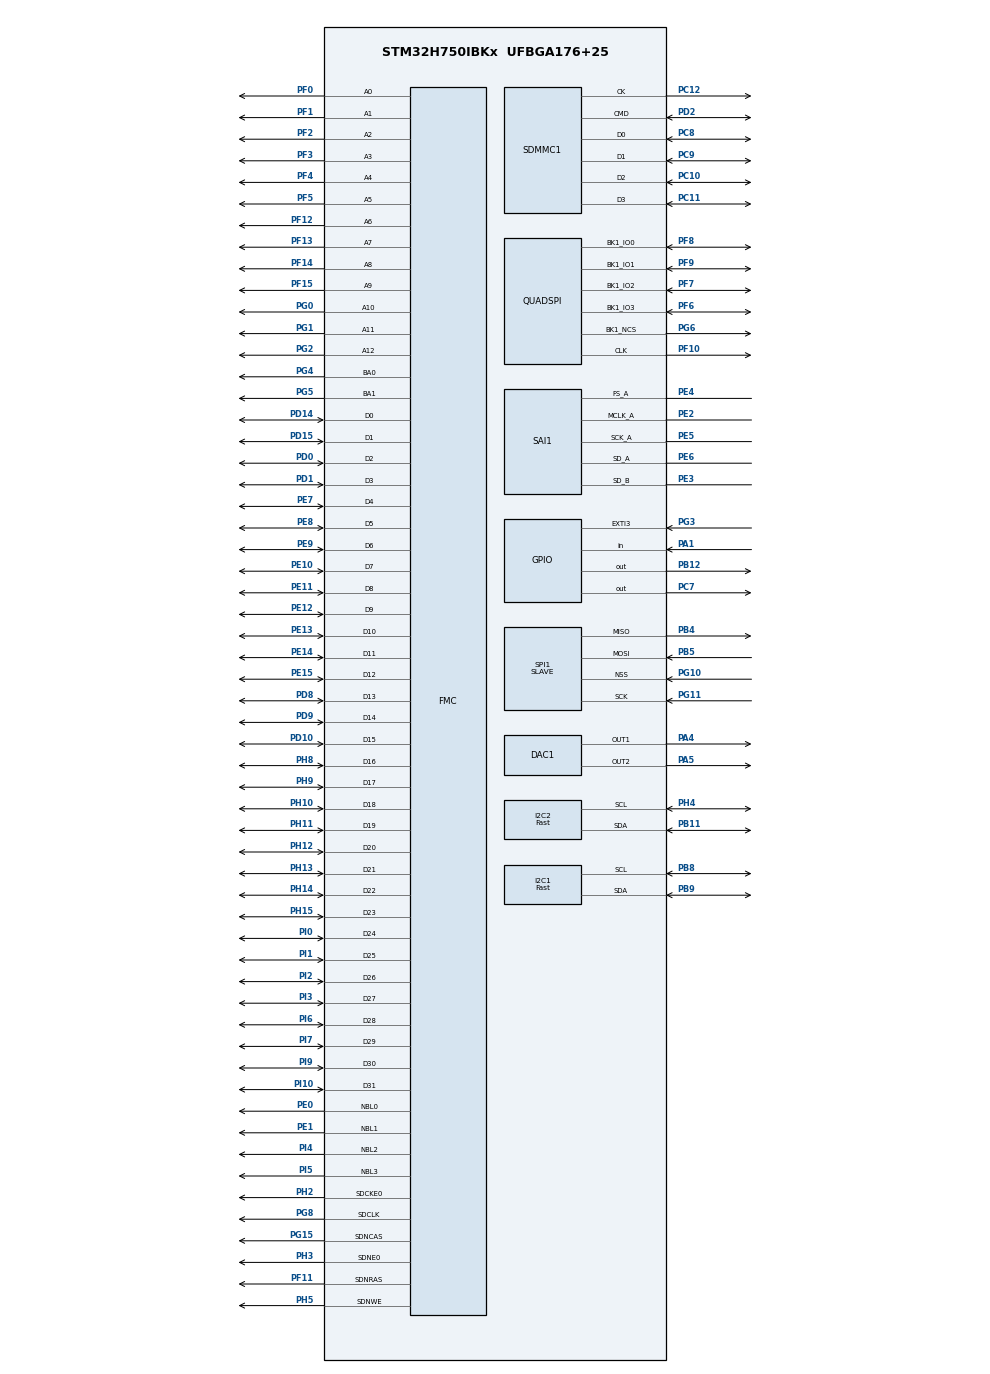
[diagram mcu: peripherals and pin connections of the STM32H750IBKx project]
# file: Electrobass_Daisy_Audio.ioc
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CORTEX_M7.CPU_DCache=Enabled
CORTEX_M7.CPU_ICache=Disabled
CORTEX_M7.default_mode_Activation=0
DAC1.DAC_Channel-DAC_OUT1=DAC_CHANNEL_1
DAC1.DAC_Channel-DAC_OUT2=DAC_CHANNEL_2
DAC1.DAC_Trigger-DAC_OUT1=DAC_TRIGGER_SOFTWARE
DAC1.DAC_Trigger-DAC_OUT2=DAC_TRIGGER_SOFTWARE
Dma.Request0=SAI1_A
Dma.Request1=SAI1_B
Dma.Request2=SPI1_RX
Dma.Request3=SPI1_TX
Dma.SAI1_A.0.Direction=DMA_PERIPH_TO_MEMORY
Dma.SAI1_A.0.EventEnable=ENABLE
Dma.SAI1_A.0.FIFOMode=DMA_FIFOMODE_DISABLE
Dma.SAI1_A.0.Instance=DMA1_Stream1
Dma.SAI1_A.0.MemDataAlignment=DMA_MDATAALIGN_WORD
Dma.SAI1_A.0.MemInc=DMA_MINC_ENABLE
Dma.SAI1_A.0.Mode=DMA_CIRCULAR
Dma.SAI1_A.0.PeriphDataAlignment=DMA_PDATAALIGN_WORD
Dma.SAI1_A.0.PeriphInc=DMA_PINC_DISABLE
Dma.SAI1_A.0.Polarity=HAL_DMAMUX_REQ_GEN_RISING
Dma.SAI1_A.0.Priority=DMA_PRIORITY_HIGH
Dma.SAI1_A.0.RequestNumber=1
Dma.SAI1_A.0.SignalID=NONE
Dma.SAI1_A.0.SyncEnable=ENABLE
Dma.SAI1_A.0.SyncPolarity=HAL_DMAMUX_SYNC_RISING
Dma.SAI1_A.0.SyncRequestNumber=1
Dma.SAI1_A.0.SyncSignalID=NONE
Dma.SAI1_B.1.Direction=DMA_MEMORY_TO_PERIPH
Dma.SAI1_B.1.EventEnable=DISABLE
Dma.SAI1_B.1.FIFOMode=DMA_FIFOMODE_DISABLE
Dma.SAI1_B.1.Instance=DMA1_Stream2
Dma.SAI1_B.1.MemDataAlignment=DMA_MDATAALIGN_WORD
Dma.SAI1_B.1.MemInc=DMA_MINC_ENABLE
Dma.SAI1_B.1.Mode=DMA_CIRCULAR
Dma.SAI1_B.1.PeriphDataAlignment=DMA_PDATAALIGN_WORD
Dma.SAI1_B.1.PeriphInc=DMA_PINC_DISABLE
Dma.SAI1_B.1.Polarity=HAL_DMAMUX_REQ_GEN_RISING
Dma.SAI1_B.1.Priority=DMA_PRIORITY_HIGH
Dma.SAI1_B.1.RequestNumber=1
Dma.SAI1_B.1.SignalID=NONE
Dma.SAI1_B.1.SyncEnable=DISABLE
Dma.SAI1_B.1.SyncPolarity=HAL_DMAMUX_SYNC_NO_EVENT
Dma.SAI1_B.1.SyncRequestNumber=1
Dma.SAI1_B.1.SyncSignalID=NONE
Dma.SPI1_RX.2.Direction=DMA_PERIPH_TO_MEMORY
Dma.SPI1_RX.2.EventEnable=DISABLE
Dma.SPI1_RX.2.FIFOMode=DMA_FIFOMODE_ENABLE
Dma.SPI1_RX.2.FIFOThreshold=DMA_FIFO_THRESHOLD_1QUARTERFULL
Dma.SPI1_RX.2.Instance=DMA1_Stream6
Dma.SPI1_RX.2.MemBurst=DMA_MBURST_SINGLE
Dma.SPI1_RX.2.MemDataAlignment=DMA_MDATAALIGN_BYTE
Dma.SPI1_RX.2.MemInc=DMA_MINC_ENABLE
Dma.SPI1_RX.2.Mode=DMA_CIRCULAR
Dma.SPI1_RX.2.PeriphBurst=DMA_PBURST_SINGLE
Dma.SPI1_RX.2.PeriphDataAlignment=DMA_PDATAALIGN_BYTE
Dma.SPI1_RX.2.PeriphInc=DMA_PINC_DISABLE
Dma.SPI1_RX.2.Polarity=HAL_DMAMUX_REQ_GEN_RISING
Dma.SPI1_RX.2.Priority=DMA_PRIORITY_VERY_HIGH
Dma.SPI1_RX.2.RequestNumber=1
Dma.SPI1_RX.2.SignalID=NONE
Dma.SPI1_RX.2.SyncEnable=DISABLE
Dma.SPI1_RX.2.SyncPolarity=HAL_DMAMUX_SYNC_NO_EVENT
Dma.SPI1_RX.2.SyncRequestNumber=1
Dma.SPI1_RX.2.SyncSignalID=NONE
Dma.SPI1_TX.3.Direction=DMA_MEMORY_TO_PERIPH
Dma.SPI1_TX.3.EventEnable=DISABLE
Dma.SPI1_TX.3.FIFOMode=DMA_FIFOMODE_ENABLE
Dma.SPI1_TX.3.FIFOThreshold=DMA_FIFO_THRESHOLD_1QUARTERFULL
Dma.SPI1_TX.3.Instance=DMA1_Stream7
Dma.SPI1_TX.3.MemBurst=DMA_MBURST_SINGLE
Dma.SPI1_TX.3.MemDataAlignment=DMA_MDATAALIGN_BYTE
Dma.SPI1_TX.3.MemInc=DMA_MINC_ENABLE
Dma.SPI1_TX.3.Mode=DMA_CIRCULAR
Dma.SPI1_TX.3.PeriphBurst=DMA_PBURST_SINGLE
Dma.SPI1_TX.3.PeriphDataAlignment=DMA_PDATAALIGN_BYTE
Dma.SPI1_TX.3.PeriphInc=DMA_PINC_DISABLE
Dma.SPI1_TX.3.Polarity=HAL_DMAMUX_REQ_GEN_RISING
Dma.SPI1_TX.3.Priority=DMA_PRIORITY_VERY_HIGH
Dma.SPI1_TX.3.RequestNumber=1
Dma.SPI1_TX.3.SignalID=NONE
Dma.SPI1_TX.3.SyncEnable=DISABLE
Dma.SPI1_TX.3.SyncPolarity=HAL_DMAMUX_SYNC_NO_EVENT
Dma.SPI1_TX.3.SyncRequestNumber=1
Dma.SPI1_TX.3.SyncSignalID=NONE
FATFS.BSP.number=1
FATFS.USE_DMA_CODE_SD=0
FATFS._FS_NORTC=0
FATFS._USE_FASTSEEK=0
FATFS._USE_FIND=1
FATFS._USE_LFN=1
FATFS0.BSP.STBoard=false
FATFS0.BSP.api=Unknown
FATFS0.BSP.instance=PA1
FATFS0.BSP.ip=GPIO
FATFS0.BSP.mode=Input
FATFS0.BSP.name=Detect_SDIO
FATFS0.BSP.solution=PA1
FMC.CASLatency1=FMC_SDRAM_CAS_LATENCY_3
FMC.ColumnBitsNumber1=FMC_SDRAM_COLUMN_BITS_NUM_9
FMC.ExitSelfRefreshDelay1=7
FMC.LoadToActiveDelay1=2
FMC.RCDDelay1=10
FMC.ReadBurst1=FMC_SDRAM_RBURST_ENABLE
FMC.ReadBurst2=FMC_SDRAM_RBURST_ENABLE
FMC.RowCycleDelay1=8
FMC.RowCycleDelay2=8
FMC.SDClockPeriod1=FMC_SDRAM_CLOCK_PERIOD_2
FMC.SDClockPeriod2=FMC_SDRAM_CLOCK_PERIOD_2
FMC.SelfRefreshTime1=4
FMC.WriteRecoveryTime1=3
I2C1.I2C_Rise_Time=300
I2C1.I2C_Speed_Mode=I2C_Fast
I2C1.Timing=0x30B00F2D
I2C2.I2C_Speed_Mode=I2C_Fast
I2C2.Timing=0x00B03FDB
Mcu.Family=STM32H7
Mcu.Name=STM32H750IBKx
Mcu.Package=UFBGA176+25
NVIC.DMA1_Stream1_IRQn=true\:3\:0\:true\:false\:true\:false\:true\:true
NVIC.DMA1_Stream2_IRQn=true\:3\:0\:true\:false\:true\:false\:true\:true
NVIC.DMA1_Stream6_IRQn=true\:2\:0\:true\:false\:true\:false\:true\:true
NVIC.DMA1_Stream7_IRQn=true\:2\:0\:true\:false\:true\:false\:true\:true
NVIC.DMAMUX1_OVR_IRQn=true\:5\:0\:true\:false\:true\:false\:true\:true
NVIC.EXTI3_IRQn=true\:1\:0\:true\:false\:true\:true\:true\:true
NVIC.PriorityGroup=NVIC_PRIORITYGROUP_4
NVIC.SAI1_IRQn=true\:3\:0\:true\:false\:true\:true\:true\:true
NVIC.SDMMC1_IRQn=true\:4\:0\:true\:false\:true\:true\:true\:true
NVIC.SPI1_IRQn=true\:2\:0\:true\:false\:true\:false\:true\:true
PA1.GPIO_PuPd=GPIO_PULLUP
PA1.Signal=GPIO_Input
PA13\ (JTMS/SWDIO).Mode=Trace_Asynchronous_SW
PA13\ (JTMS/SWDIO).Signal=DEBUG_JTMS-SWDIO
PA14\ (JTCK/SWCLK).Mode=Trace_Asynchronous_SW
PA14\ (JTCK/SWCLK).Signal=DEBUG_JTCK-SWCLK
PA4.Signal=COMP_DAC11_group
PA5.Signal=COMP_DAC12_group
PB11.GPIO_Speed=GPIO_SPEED_FREQ_MEDIUM
PB11.Mode=I2C
PB11.Signal=I2C2_SDA
PB12.Signal=GPIO_Output
PB14.Signal=USB_OTG_HS_DM
PB15.Signal=USB_OTG_HS_DP
PB3\ (JTDO/TRACESWO).Mode=Trace_Asynchronous_SW
PB3\ (JTDO/TRACESWO).Signal=DEBUG_JTDO-SWO
PB4\ (NJTRST).GPIO_Speed=GPIO_SPEED_FREQ_HIGH
PB4\ (NJTRST).Mode=Full_Duplex_Slave
PB4\ (NJTRST).Signal=SPI1_MISO
PB5.GPIO_Speed=GPIO_SPEED_FREQ_HIGH
PB5.Mode=Full_Duplex_Slave
PB5.Signal=SPI1_MOSI
PB8.Mode=I2C
PB8.Signal=I2C1_SCL
PB9.Mode=I2C
PB9.Signal=I2C1_SDA
PC10.GPIO_PuPd=GPIO_PULLUP
PC10.GPIO_Speed_High_Default=GPIO_SPEED_FREQ_HIGH
PC10.Mode=SD_4_bits_Wide_bus
PC10.Signal=SDMMC1_D2
PC11.GPIO_PuPd=GPIO_PULLUP
PC11.GPIO_Speed_High_Default=GPIO_SPEED_FREQ_HIGH
PC11.Mode=SD_4_bits_Wide_bus
PC11.Signal=SDMMC1_D3
PC12.GPIO_PuPd=GPIO_PULLUP
PC12.GPIO_Speed_High_Default=GPIO_SPEED_FREQ_HIGH
PC12.Mode=SD_4_bits_Wide_bus
PC12.Signal=SDMMC1_CK
PC7.Signal=GPIO_Output
PC8.GPIO_PuPd=GPIO_PULLUP
PC8.GPIO_Speed_High_Default=GPIO_SPEED_FREQ_HIGH
PC8.Mode=SD_4_bits_Wide_bus
PC8.Signal=SDMMC1_D0
PC9.GPIO_PuPd=GPIO_PULLUP
PC9.GPIO_Speed_High_Default=GPIO_SPEED_FREQ_HIGH
PC9.Mode=SD_4_bits_Wide_bus
PC9.Signal=SDMMC1_D1
PD0.Signal=FMC_D2_DA2
PD1.Signal=FMC_D3_DA3
PD10.Signal=FMC_D15_DA15
PD14.Signal=FMC_D0_DA0
PD15.Signal=FMC_D1_DA1
PD2.GPIO_PuPd=GPIO_PULLUP
PD2.GPIO_Speed_High_Default=GPIO_SPEED_FREQ_HIGH
PD2.Mode=SD_4_bits_Wide_bus
PD2.Signal=SDMMC1_CMD
PD8.Signal=FMC_D13_DA13
PD9.Signal=FMC_D14_DA14
PE0.Signal=FMC_NBL0
PE1.Signal=FMC_NBL1
PE10.Signal=FMC_D7_DA7
PE11.Signal=FMC_D8_DA8
PE12.Signal=FMC_D9_DA9
PE13.Signal=FMC_D10_DA10
PE14.Signal=FMC_D11_DA11
PE15.Signal=FMC_D12_DA12
PE2.GPIO_Speed=GPIO_SPEED_FREQ_HIGH
PE2.Mode=SAI_A_MasterWithClock
PE2.Signal=SAI1_MCLK_A
PE3.GPIO_Speed=GPIO_SPEED_FREQ_HIGH
PE3.Mode=SAI_B_SyncSlave
PE3.Signal=SAI1_SD_B
PE4.GPIO_Speed=GPIO_SPEED_FREQ_HIGH
PE4.Mode=SAI_A_MasterWithClock
PE4.Signal=SAI1_FS_A
PE5.GPIO_Speed=GPIO_SPEED_FREQ_HIGH
PE5.Mode=SAI_A_MasterWithClock
PE5.Signal=SAI1_SCK_A
PE6.GPIO_Speed=GPIO_SPEED_FREQ_HIGH
PE6.Mode=SAI_A_MasterWithClock
PE6.Signal=SAI1_SD_A
PE7.Signal=FMC_D4_DA4
PE8.Signal=FMC_D5_DA5
PE9.Signal=FMC_D6_DA6
PF0.Signal=FMC_A0
PF1.Signal=FMC_A1
PF10.Mode=Single Bank 1
PF10.Signal=QUADSPI_CLK
PF11.Signal=FMC_SDNRAS
PF12.Signal=FMC_A6
PF13.Signal=FMC_A7
PF14.Signal=FMC_A8
PF15.Signal=FMC_A9
PF2.Signal=FMC_A2
PF3.Signal=FMC_A3
PF4.Signal=FMC_A4
PF5.Signal=FMC_A5
PF6.Mode=Single Bank 1
PF6.Signal=QUADSPI_BK1_IO3
PF7.Mode=Single Bank 1
PF7.Signal=QUADSPI_BK1_IO2
PF8.Mode=Single Bank 1
PF8.Signal=QUADSPI_BK1_IO0
PF9.Mode=Single Bank 1
PF9.Signal=QUADSPI_BK1_IO1
PG0.Signal=FMC_A10
PG1.Signal=FMC_A11
PG10.GPIO_Speed=GPIO_SPEED_FREQ_HIGH
PG10.Mode=NSS_Signal_Hard_Input
PG10.Signal=SPI1_NSS
PG11.GPIO_Speed=GPIO_SPEED_FREQ_HIGH
PG11.Mode=Full_Duplex_Slave
PG11.Signal=SPI1_SCK
PG15.Signal=FMC_SDNCAS
PG2.Signal=FMC_A12
PG3.GPIO_ModeDefaultEXTI=GPIO_MODE_IT_RISING_FALLING
PG3.Signal=GPXTI3
PG4.Signal=FMC_A14_BA0
PG5.Signal=FMC_A15_BA1
PG6.Mode=Single Bank 1
PG6.Signal=QUADSPI_BK1_NCS
PG8.Signal=FMC_SDCLK
PH0-OSC_IN\ (PH0).Mode=HSE-External-Oscillator
PH0-OSC_IN\ (PH0).Signal=RCC_OSC_IN
PH1-OSC_OUT\ (PH1).Mode=HSE-External-Oscillator
PH1-OSC_OUT\ (PH1).Signal=RCC_OSC_OUT
PH10.Signal=FMC_D18
PH11.Signal=FMC_D19
PH12.Signal=FMC_D20
PH13.Signal=FMC_D21
PH14.Signal=FMC_D22
PH15.Signal=FMC_D23
PH2.Mode=SdramChipSelect1_1
PH2.Signal=FMC_SDCKE0
PH3.Mode=SdramChipSelect1_1
PH3.Signal=FMC_SDNE0
PH4.GPIO_Speed=GPIO_SPEED_FREQ_MEDIUM
PH4.Mode=I2C
PH4.Signal=I2C2_SCL
PH5.Signal=FMC_SDNWE
PH8.Signal=FMC_D16
PH9.Signal=FMC_D17
PI0.Signal=FMC_D24
PI1.Signal=FMC_D25
PI10.Signal=FMC_D31
PI2.Signal=FMC_D26
PI3.Signal=FMC_D27
PI4.Signal=FMC_NBL2
PI5.Signal=FMC_NBL3
PI6.Signal=FMC_D28
PI7.Signal=FMC_D29
PI9.Signal=FMC_D30
ProjectManager.HeapSize=0x4000
ProjectManager.StackSize=0x8000
ProjectManager.TargetToolchain=STM32CubeIDE
QUADSPI.ClockPrescaler=1
QUADSPI.FlashSize=19
RCC.ADCCLockSelection=RCC_ADCCLKSOURCE_PLL3
RCC.ADCFreq_Value=12288085.9375
RCC.APB1Freq_Value=120000000
RCC.APB2Freq_Value=120000000
RCC.APB3Freq_Value=120000000
RCC.APB4Freq_Value=120000000
RCC.CKPERSourceSelection=RCC_CLKPSOURCE_HSE
RCC.CortexFreq_Value=480000000
RCC.D1PPRE=RCC_APB3_DIV2
RCC.D2PPRE1=RCC_APB1_DIV2
RCC.D2PPRE2=RCC_APB2_DIV2
RCC.D3PPRE=RCC_APB4_DIV2
RCC.DIVM1=1
RCC.DIVM2=1
RCC.DIVM3=1
RCC.DIVN1=60
RCC.DIVN2=10
RCC.DIVN3=12
RCC.DIVP2=8
RCC.DIVP3=4
RCC.DIVQ1=6
RCC.DIVQ3=8
RCC.DIVR1=8
RCC.DIVR2=1
RCC.DIVR3=16
RCC.FMCCLockSelection=RCC_FMCCLKSOURCE_PLL2
RCC.HCLKFreq_Value=240000000
RCC.HPRE=RCC_HCLK_DIV2
RCC.HSE_VALUE=16000000
RCC.PLL2FRACN=4096
RCC.PLL3FRACN=2360
RCC.PLLFRACN=0
RCC.PLLSourceVirtual=RCC_PLLSOURCE_HSE
RCC.ProductRev=revV
RCC.QSPICLockSelection=RCC_QSPICLKSOURCE_PLL
RCC.SAI1CLockSelection=RCC_SAI1CLKSOURCE_PLL3
RCC.SAI23CLockSelection=RCC_SAI23CLKSOURCE_PLL3
RCC.SDMMC1CLockSelection=RCC_SDMMCCLKSOURCE_PLL2
RCC.SYSCLKFreq_VALUE=480000000
RCC.SYSCLKSource=RCC_SYSCLKSOURCE_PLLCLK
RCC.USBCLockSelection=RCC_USBCLKSOURCE_HSI48
RCC.USBFreq_Value=48000000
SAI1.AudioFrequency-SAI_A_MasterWithClock=SAI_AUDIO_FREQUENCY_48K
SAI1.AudioMode-SAI_A_MasterWithClock=SAI_MODEMASTER_RX
SAI1.AudioMode-SAI_B_SyncSlave=SAI_MODESLAVE_TX
SAI1.BasicDataSize-SAI_A_MasterWithClock=SAI_PROTOCOL_DATASIZE_24BIT
SAI1.BasicDataSize-SAI_B_SyncSlave=SAI_PROTOCOL_DATASIZE_24BIT
SAI1.BasicProtocol-SAI_A_MasterWithClock=SAI_I2S_MSBJUSTIFIED
SAI1.BasicProtocol-SAI_B_SyncSlave=SAI_I2S_MSBJUSTIFIED
SAI1.ErrorAudioFreq-SAI_A_MasterWithClock=300.0 %
SAI1.InitProtocol-SAI_A_MasterWithClock=Enable
SAI1.InitProtocol-SAI_B_SyncSlave=Enable
SAI1.Instance-SAI_A_MasterWithClock=SAI$Index_Block_A
SAI1.Instance-SAI_B_SyncSlave=SAI$Index_Block_B
SAI1.MClockEnable-SAI_A_MasterWithClock=SAI_MASTERCLOCK_ENABLE
SAI1.RealAudioFreq-SAI_A_MasterWithClock=192.001 KHz
SAI1.VirtualMode-SAI_A_MasterWithClock=VM_MASTER
SAI1.VirtualMode-SAI_B_SyncSlave=VM_SLAVE
SAI1.VirtualProtocol-SAI_A_BASIC=VM_BASIC_PROTOCOL
SAI1.VirtualProtocol-SAI_B_BASIC=VM_BASIC_PROTOCOL
SDMMC1.ClockDiv=25
SDMMC1.USE_SD_TRANSCEIVER=0U
SH.COMP_DAC11_group.0=DAC1_OUT1,DAC_OUT1
SH.COMP_DAC12_group.0=DAC1_OUT2,DAC_OUT2
SH.FMC_A0.0=FMC_A0,13b-sda1
SH.FMC_A1.0=FMC_A1,13b-sda1
SH.FMC_A10.0=FMC_A10,13b-sda1
SH.FMC_A11.0=FMC_A11,13b-sda1
SH.FMC_A12.0=FMC_A12,13b-sda1
SH.FMC_A14_BA0.0=FMC_BA0,FourSdramBanks1
SH.FMC_A15_BA1.0=FMC_BA1,FourSdramBanks1
SH.FMC_A2.0=FMC_A2,13b-sda1
SH.FMC_A3.0=FMC_A3,13b-sda1
SH.FMC_A4.0=FMC_A4,13b-sda1
SH.FMC_A5.0=FMC_A5,13b-sda1
SH.FMC_A6.0=FMC_A6,13b-sda1
SH.FMC_A7.0=FMC_A7,13b-sda1
SH.FMC_A8.0=FMC_A8,13b-sda1
SH.FMC_A9.0=FMC_A9,13b-sda1
SH.FMC_D0_DA0.0=FMC_D0,sd-32b-d1
SH.FMC_D10_DA10.0=FMC_D10,sd-32b-d1
SH.FMC_D11_DA11.0=FMC_D11,sd-32b-d1
SH.FMC_D12_DA12.0=FMC_D12,sd-32b-d1
SH.FMC_D13_DA13.0=FMC_D13,sd-32b-d1
SH.FMC_D14_DA14.0=FMC_D14,sd-32b-d1
SH.FMC_D15_DA15.0=FMC_D15,sd-32b-d1
SH.FMC_D16.0=FMC_D16,sd-32b-d1
SH.FMC_D17.0=FMC_D17,sd-32b-d1
SH.FMC_D18.0=FMC_D18,sd-32b-d1
SH.FMC_D19.0=FMC_D19,sd-32b-d1
SH.FMC_D1_DA1.0=FMC_D1,sd-32b-d1
SH.FMC_D20.0=FMC_D20,sd-32b-d1
SH.FMC_D21.0=FMC_D21,sd-32b-d1
SH.FMC_D22.0=FMC_D22,sd-32b-d1
SH.FMC_D23.0=FMC_D23,sd-32b-d1
SH.FMC_D24.0=FMC_D24,sd-32b-d1
SH.FMC_D25.0=FMC_D25,sd-32b-d1
SH.FMC_D26.0=FMC_D26,sd-32b-d1
SH.FMC_D27.0=FMC_D27,sd-32b-d1
SH.FMC_D28.0=FMC_D28,sd-32b-d1
SH.FMC_D29.0=FMC_D29,sd-32b-d1
SH.FMC_D2_DA2.0=FMC_D2,sd-32b-d1
SH.FMC_D30.0=FMC_D30,sd-32b-d1
SH.FMC_D31.0=FMC_D31,sd-32b-d1
SH.FMC_D3_DA3.0=FMC_D3,sd-32b-d1
SH.FMC_D4_DA4.0=FMC_D4,sd-32b-d1
SH.FMC_D5_DA5.0=FMC_D5,sd-32b-d1
SH.FMC_D6_DA6.0=FMC_D6,sd-32b-d1
SH.FMC_D7_DA7.0=FMC_D7,sd-32b-d1
SH.FMC_D8_DA8.0=FMC_D8,sd-32b-d1
SH.FMC_D9_DA9.0=FMC_D9,sd-32b-d1
SH.FMC_NBL0.0=FMC_NBL0,Sd4ByteEnable1
SH.FMC_NBL1.0=FMC_NBL1,Sd4ByteEnable1
SH.FMC_NBL2.0=FMC_NBL2,Sd4ByteEnable1
SH.FMC_NBL3.0=FMC_NBL3,Sd4ByteEnable1
SH.FMC_SDCLK.0=FMC_SDCLK,13b-sda1
SH.FMC_SDNCAS.0=FMC_SDNCAS,13b-sda1
SH.FMC_SDNRAS.0=FMC_SDNRAS,13b-sda1
SH.FMC_SDNWE.0=FMC_SDNWE,13b-sda1
SPI1.DataSize=SPI_DATASIZE_8BIT
SPI1.Direction=SPI_DIRECTION_2LINES
SPI1.Mode=SPI_MODE_SLAVE
SPI1.VirtualNSS=VM_NSSHARD
SPI1.VirtualType=VM_SLAVE
VP_FATFS_VS_SDIO.Mode=SDIO
VP_RNG_VS_RNG.Mode=RNG_Activate
VP_SAI1_VP_$IpInstance_SAIA_SAI_BASIC.Mode=SAI_A_BASIC
VP_SAI1_VP_$IpInstance_SAIB_SAI_BASIC.Mode=SAI_B_BASIC
board=custom

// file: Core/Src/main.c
/* USER CODE BEGIN Header */
/**
  ******************************************************************************
  * @file           : main.c
  * @brief          : Main program body
  ******************************************************************************
  * @attention
  *
  * Copyright (c) 2022 STMicroelectronics.
  * All rights reserved.
  *
  * This software is licensed under terms that can be found in the LICENSE file
  * in the root directory of this software component.
  * If no LICENSE file comes with this software, it is provided AS-IS.
  *
  ******************************************************************************
  */
/* USER CODE END Header */
#include "main.h"
#include "dac.h"
#include "dma.h"
#include "fatfs.h"
#include "i2c.h"
#include "quadspi.h"
#include "rng.h"
#include "sai.h"
#include "sdmmc.h"
#include "spi.h"
#include "gpio.h"
#include "fmc.h"

/* USER CODE BEGIN Includes */
#include "leaf.h"
#include "codec.h"
#include "audio.h"
/* USER CODE END Includes */

void SystemClock_Config(void);
void PeriphCommonClock_Config(void);
/* USER CODE BEGIN PFP */
void MPU_Conf(void);
static int checkForSDCardPreset(uint8_t value);
static void writePresetToSDCard(int fileSize);
static int checkForSDCardTuning(uint8_t numberToLoad);
static void writeTuningToSDCard(int fileSize);

void parsePreset(int size, int presetNumber);

void __ATTR_ITCMRAM parseTuning(int size, int tuningNumber);

void getPresetNamesFromSDCard(void);
void getTuningNamesFromSDCard(void);
/* USER CODE END PFP */

/* USER CODE BEGIN 0 */

#define SPI_BUFFER_SIZE 32
#define SPI_FRAME_SIZE 16
uint8_t SPI_TX[SPI_BUFFER_SIZE] __ATTR_RAM_D2;
uint8_t SPI_RX[SPI_BUFFER_SIZE] __ATTR_RAM_D2;

float random_values[256] __ATTR_DTCMRAM;
uint8_t currentRandom = 0;

uint8_t bootloaderFlag[32] __ATTR_USER_FLASH;
uint8_t resetFlag = 0;

uint8_t diskBusy = 0;
uint8_t buttonPressed = 0;
FILINFO fno;
DIR dir;
const TCHAR path = 0;

#define MAX_NUM_PRESETS 20
#define MAX_NUM_TUNINGS 20
volatile uint8_t writingState = 0;
volatile float 	audioMasterLevel = 1.0f;
FIL fdst;
uint8_t buffer[4096];
volatile uint16_t bufferPos = 0;
FRESULT res;
uint8_t presetNumberToSave;
uint8_t presetNumberToLoad = 0;
uint8_t tuningNumberToSave;
uint8_t tuningNumberToLoad = 0;
uint8_t currentActivePreset = 0;
uint8_t presetName[14];
volatile uint8_t presetNamesArray[MAX_NUM_PRESETS][14];
uint8_t whichPresetToSendName = 0;
volatile uint8_t tuningNamesArray[MAX_NUM_TUNINGS][14];
uint8_t whichTuningToSendName = 0;
uint8_t tuningName[14];
uint32_t presetWaitingToParse = 0;
uint32_t presetWaitingToWrite = 0;
uint32_t presetWaitingToLoad = 0;
uint32_t tuningWaitingToParse = 0;
uint32_t tuningWaitingToWrite = 0;
uint32_t tuningWaitingToLoad = 0;

uint8_t sendPresetName = 1;

param params[NUM_PARAMS];
mapping mappings[MAX_NUM_MAPPINGS];
uint8_t numMappings = 0;

filterSetter filterSetters[NUM_FILT];
lfoSetter lfoSetters[NUM_LFOS];
effectSetter effectSetters[NUM_EFFECT];
float defaultScaling = 1.0f;

#define SCALE_TABLE_SIZE 2048
float resTable[SCALE_TABLE_SIZE];
float envTimeTable[SCALE_TABLE_SIZE];
float lfoRateTable[SCALE_TABLE_SIZE];

float midiKeyDivisor;
float midiKeySubtractor;

uint8_t volatile interruptChecker = 0;

uint8_t volatile foundOne = 0;
uint8_t loadFailed = 0;
uint32_t volatile myTestInt = 0;

/* USER CODE END 0 */

int main(void)
{
  /* USER CODE BEGIN 1 */
  MPU_Conf();
  SCB_EnableICache();
  /* USER CODE END 1 */

  /* Enable D-Cache---------------------------------------------------------*/
  SCB_EnableDCache();

  /* MCU Configuration--------------------------------------------------------*/

  /* Reset of all peripherals, Initializes the Flash interface and the Systick. */
  HAL_Init();

  /* USER CODE BEGIN Init */
  __enable_irq();
  /* USER CODE END Init */

  /* Configure the system clock */
  SystemClock_Config();

/* Configure the peripherals common clocks */
  PeriphCommonClock_Config();

  /* Initialize all configured peripherals */
  MX_GPIO_Init();
  MX_DMA_Init();
  MX_DAC1_Init();
  MX_FMC_Init();
  MX_I2C2_Init();
  MX_QUADSPI_Init();
  MX_SAI1_Init();
  MX_SDMMC1_SD_Init();
  MX_SPI1_Init();
  MX_I2C1_Init();
  MX_RNG_Init();
  MX_FATFS_Init();
  /* USER CODE BEGIN 2 */
  /* Enable write access to Backup domain */
   PWR->CR1 |= PWR_CR1_DBP;
   while((PWR->CR1 & PWR_CR1_DBP) == RESET)
   {
	   ;
   }
   /*Enable BKPRAM clock*/
   __HAL_RCC_BKPRAM_CLK_ENABLE();

   HAL_GPIO_WritePin(GPIOC, GPIO_PIN_7, GPIO_PIN_RESET);
  uint32_t tempFPURegisterVal = __get_FPSCR();
  tempFPURegisterVal |= (1<<24); // set the FTZ (flush-to-zero) bit in the FPU control register
  __set_FPSCR(tempFPURegisterVal);

  CycleCounterInit();
  cStack_init(&midiStack);

  for (int i = 0; i < 128; i++){
	  fractionalMidi[i] = i;
  }
  for (int i = 0; i < 4096; i++)
  {
	  buffer[i] = 0;
  } //put in some values to make the array valid as a preset
  buffer[15+112] = NUM_PARAMS;
  buffer[NUM_PARAMS*2+16+112] = 0xef;
  buffer[NUM_PARAMS*2+17+112] = 0xef;
  buffer[NUM_PARAMS*2+19+112] = 1;
  buffer[NUM_PARAMS*2+25+112] = 0xfe;
  buffer[NUM_PARAMS*2+26+112] = 0xfe;

  tuningNamesArray[0][0] = 'E';
  tuningNamesArray[0][1] = 'T';
  LEAF_generate_table_skew_non_sym(resTable, 0.01f, 10.0f, 0.5f, SCALE_TABLE_SIZE);
  LEAF_generate_table_skew_non_sym(envTimeTable, 0.0f, 20000.0f, 4000.0f, SCALE_TABLE_SIZE);
  LEAF_generate_table_skew_non_sym(lfoRateTable, 0.0f, 30.0f, 2.0f, SCALE_TABLE_SIZE);

  HAL_Delay(10);
  getPresetNamesFromSDCard();
  foundOne  = checkForSDCardPreset(presetNumberToLoad);

  codec_init(&hi2c2);

  audio_init();

  if (foundOne == 0)
  {
	  parsePreset((NUM_PARAMS*2)+27+ (8*14), 0); //default preset binary
  }
  else
  {
	  //HAL_GPIO_WritePin(GPIOC, GPIO_PIN_7, GPIO_PIN_SET);
	  parsePreset(presetWaitingToParse, presetNumberToLoad);
  }

  int counter = 0;
  for (int i = 0; i < SPI_BUFFER_SIZE; i++)
  {
	  SPI_TX[i] = counter++;
  }

  HAL_Delay(10);

  HAL_SPI_TransmitReceive_DMA(&hspi1, SPI_TX, SPI_RX, SPI_BUFFER_SIZE);

  HAL_GPIO_WritePin(GPIOB, GPIO_PIN_12, GPIO_PIN_SET);
  audio_start(&hsai_BlockB1, &hsai_BlockA1);

  /* USER CODE END 2 */

  /* Infinite loop */
  /* USER CODE BEGIN WHILE */
  while (1)
  {
	  if (presetWaitingToLoad > 0)
	  {
		  checkForSDCardPreset(presetNumberToLoad);
	  }

	  if (presetWaitingToParse > 0)
	  {
		  parsePreset(presetWaitingToParse, presetNumberToLoad);
	  }

	  else if (presetWaitingToWrite > 0)
	  {
		  writePresetToSDCard(presetWaitingToWrite);
	  }

	  if (tuningWaitingToLoad > 0)
	  {
		  checkForSDCardTuning(tuningNumberToLoad);
	  }
	  if(tuningWaitingToParse > 0)
	  {
		  parseTuning(tuningWaitingToParse, tuningNumberToLoad);
	  }
	  else if  (tuningWaitingToWrite)
	  {
		  writeTuningToSDCard(tuningWaitingToWrite);
	  }

	  uint32_t rand;
	  HAL_RNG_GenerateRandomNumber(&hrng, &rand);

	  if (rand > TWO_TO_31)
	  {
		  myTestInt++;
		  //HAL_GPIO_TogglePin(GPIOC, GPIO_PIN_7);
	  }
	  float floatrand = (float)rand * INV_TWO_TO_32 ;
	  random_values[currentRandom++] = (floatrand * 2.0f) - 1.0f;
	  /*

	  */
	  //HAL_GPIO_TogglePin(GPIOC, GPIO_PIN_7);
	  //HAL_Delay(200);
    /* USER CODE END WHILE */

  }
}

void SystemClock_Config(void)
{
  RCC_OscInitTypeDef RCC_OscInitStruct = {0};
  RCC_ClkInitTypeDef RCC_ClkInitStruct = {0};

  /** Supply configuration update enable
  */
  HAL_PWREx_ConfigSupply(PWR_LDO_SUPPLY);

  /** Configure the main internal regulator output voltage
  */
  __HAL_PWR_VOLTAGESCALING_CONFIG(PWR_REGULATOR_VOLTAGE_SCALE1);

  while(!__HAL_PWR_GET_FLAG(PWR_FLAG_VOSRDY)) {}

  __HAL_RCC_SYSCFG_CLK_ENABLE();
  __HAL_PWR_VOLTAGESCALING_CONFIG(PWR_REGULATOR_VOLTAGE_SCALE0);

  while(!__HAL_PWR_GET_FLAG(PWR_FLAG_VOSRDY)) {}

  /** Macro to configure the PLL clock source
  */
  __HAL_RCC_PLL_PLLSOURCE_CONFIG(RCC_PLLSOURCE_HSE);

  /** Initializes the RCC Oscillators according to the specified parameters
  * in the RCC_OscInitTypeDef structure.
  */
  RCC_OscInitStruct.OscillatorType = RCC_OSCILLATORTYPE_HSI48|RCC_OSCILLATORTYPE_HSE;
  RCC_OscInitStruct.HSEState = RCC_HSE_ON;
  RCC_OscInitStruct.HSI48State = RCC_HSI48_ON;
  RCC_OscInitStruct.PLL.PLLState = RCC_PLL_ON;
  RCC_OscInitStruct.PLL.PLLSource = RCC_PLLSOURCE_HSE;
  RCC_OscInitStruct.PLL.PLLM = 1;
  RCC_OscInitStruct.PLL.PLLN = 60;
  RCC_OscInitStruct.PLL.PLLP = 2;
  RCC_OscInitStruct.PLL.PLLQ = 6;
  RCC_OscInitStruct.PLL.PLLR = 8;
  RCC_OscInitStruct.PLL.PLLRGE = RCC_PLL1VCIRANGE_3;
  RCC_OscInitStruct.PLL.PLLVCOSEL = RCC_PLL1VCOWIDE;
  RCC_OscInitStruct.PLL.PLLFRACN = 0;
  if (HAL_RCC_OscConfig(&RCC_OscInitStruct) != HAL_OK)
  {
    Error_Handler();
  }

  /** Initializes the CPU, AHB and APB buses clocks
  */
  RCC_ClkInitStruct.ClockType = RCC_CLOCKTYPE_HCLK|RCC_CLOCKTYPE_SYSCLK
                              |RCC_CLOCKTYPE_PCLK1|RCC_CLOCKTYPE_PCLK2
                              |RCC_CLOCKTYPE_D3PCLK1|RCC_CLOCKTYPE_D1PCLK1;
  RCC_ClkInitStruct.SYSCLKSource = RCC_SYSCLKSOURCE_PLLCLK;
  RCC_ClkInitStruct.SYSCLKDivider = RCC_SYSCLK_DIV1;
  RCC_ClkInitStruct.AHBCLKDivider = RCC_HCLK_DIV2;
  RCC_ClkInitStruct.APB3CLKDivider = RCC_APB3_DIV2;
  RCC_ClkInitStruct.APB1CLKDivider = RCC_APB1_DIV2;
  RCC_ClkInitStruct.APB2CLKDivider = RCC_APB2_DIV2;
  RCC_ClkInitStruct.APB4CLKDivider = RCC_APB4_DIV2;

  if (HAL_RCC_ClockConfig(&RCC_ClkInitStruct, FLASH_LATENCY_4) != HAL_OK)
  {
    Error_Handler();
  }
}

void PeriphCommonClock_Config(void)
{
  RCC_PeriphCLKInitTypeDef PeriphClkInitStruct = {0};

  /** Initializes the peripherals clock
  */
  PeriphClkInitStruct.PeriphClockSelection = RCC_PERIPHCLK_FMC|RCC_PERIPHCLK_SDMMC
                              |RCC_PERIPHCLK_SAI1;
  PeriphClkInitStruct.PLL2.PLL2M = 1;
  PeriphClkInitStruct.PLL2.PLL2N = 10;
  PeriphClkInitStruct.PLL2.PLL2P = 8;
  PeriphClkInitStruct.PLL2.PLL2Q = 2;
  PeriphClkInitStruct.PLL2.PLL2R = 1;
  PeriphClkInitStruct.PLL2.PLL2RGE = RCC_PLL2VCIRANGE_3;
  PeriphClkInitStruct.PLL2.PLL2VCOSEL = RCC_PLL2VCOMEDIUM;
  PeriphClkInitStruct.PLL2.PLL2FRACN = 4096;
  PeriphClkInitStruct.PLL3.PLL3M = 1;
  PeriphClkInitStruct.PLL3.PLL3N = 12;
  PeriphClkInitStruct.PLL3.PLL3P = 4;
  PeriphClkInitStruct.PLL3.PLL3Q = 8;
  PeriphClkInitStruct.PLL3.PLL3R = 16;
  PeriphClkInitStruct.PLL3.PLL3RGE = RCC_PLL3VCIRANGE_3;
  PeriphClkInitStruct.PLL3.PLL3VCOSEL = RCC_PLL3VCOWIDE;
  PeriphClkInitStruct.PLL3.PLL3FRACN = 2360;
  PeriphClkInitStruct.FmcClockSelection = RCC_FMCCLKSOURCE_PLL2;
  PeriphClkInitStruct.SdmmcClockSelection = RCC_SDMMCCLKSOURCE_PLL2;
  PeriphClkInitStruct.Sai1ClockSelection = RCC_SAI1CLKSOURCE_PLL3;
  if (HAL_RCCEx_PeriphCLKConfig(&PeriphClkInitStruct) != HAL_OK)
  {
    Error_Handler();
  }
}

/* USER CODE BEGIN 4 */
float  __ATTR_ITCMRAM randomNumber(void) {

	uint32_t rand;
	rand = hrng.Instance->DR; //should be faster, just may be that number isn't ready yet so we get repeated values. Unlikely at the rate we are polling it
	//HAL_RNG_GenerateRandomNumber(&hrng, &rand);
	return ((float)rand * INV_TWO_TO_32);
}

void getPresetNamesFromSDCard(void)
{
	if(BSP_SD_IsDetected())
	{
		diskBusy = 1;
		loadFailed = 0;
		//HAL_Delay(300);

		disk_initialize(0);

	    disk_status(0);

		if(f_mount(&SDFatFS,  SDPath, 1) == FR_OK)
		{

			FRESULT res;
			/* Start to search for preset files */

			//turn the integer value into a 2 digit string
			char charBuf[10];
			char finalString[10];

			for(int i = 0; i < MAX_NUM_PRESETS; i++)
			{
				itoa(i, charBuf, 10);
				int len = ((strlen(charBuf)));
				if (len == 1)
				{
					finalString[2] = charBuf[1];
					finalString[1] = charBuf[0];
					finalString[0] = '0';
					strcat(finalString, ".ebp");
				}

				else
				{
					strcat(charBuf, ".ebp");
					strcpy(finalString, charBuf);
				}

				res = f_findfirst(&dir, &fno, SDPath, finalString);
				unsigned int bytesRead;
				if(res == FR_OK)
				{
					if(f_open(&SDFile, fno.fname, FA_OPEN_ALWAYS | FA_READ) == FR_OK)
					{
						f_read(&SDFile, &buffer, f_size(&SDFile), &bytesRead);
						f_close(&SDFile);
						for (int j = 0; j < 14; j++)
						{
							presetNamesArray[i][j] = buffer[j];
						}
					}
				}
			}
			for(int i = 0; i < MAX_NUM_TUNINGS; i++)
			{
				itoa(i, charBuf, 10);
				int len = ((strlen(charBuf)));
				if (len == 1)
				{
					finalString[2] = charBuf[1];
					finalString[1] = charBuf[0];
					finalString[0] = '0';
					strcat(finalString, ".ebt");
				}

				else
				{
					strcat(charBuf, ".ebt");
					strcpy(finalString, charBuf);
				}

				res = f_findfirst(&dir, &fno, SDPath, finalString);
				unsigned int bytesRead;
				if(res == FR_OK)
				{
					if(f_open(&SDFile, fno.fname, FA_OPEN_ALWAYS | FA_READ) == FR_OK)
					{
						f_read(&SDFile, &buffer, f_size(&SDFile), &bytesRead);
						f_close(&SDFile);
						for (int j = 0; j < 14; j++)
						{
							tuningNamesArray[i][j] = buffer[j];
						}
					}
				}
			}

		}

	}
	diskBusy = 0;
	return;
}

static int checkForSDCardPreset(uint8_t numberToLoad)
{
	int found = 0;
	if(BSP_SD_IsDetected())
	{
		diskBusy = 1;
		loadFailed = 0;
		//HAL_Delay(300);

		disk_initialize(0);

	    disk_status(0);

		if(f_mount(&SDFatFS,  SDPath, 1) == FR_OK)
		{

			FRESULT res;
			/* Start to search for preset files */
			char charBuf[10];
			char finalString[10];

			//turn the integer value into a 2 digit string

			itoa(numberToLoad, charBuf, 10);
			int len = ((strlen(charBuf)));
			if (len == 1)
			{
				finalString[2] = charBuf[1];
				finalString[1] = charBuf[0];
				finalString[0] = '0';
				strcat(finalString, ".ebp");
			}

			else
			{
				strcat(charBuf, ".ebp");
				strcpy(finalString, charBuf);
			}

			res = f_findfirst(&dir, &fno, SDPath, finalString);
			unsigned int bytesRead;
			if(res == FR_OK)
			{
				if(f_open(&SDFile, fno.fname, FA_OPEN_ALWAYS | FA_READ) == FR_OK)
				{
					f_read(&SDFile, &buffer, f_size(&SDFile), &bytesRead);
					presetWaitingToParse = bytesRead;
					f_close(&SDFile);
					found = 1;
					for (int i = 0; i < 4; i++)
					{
						//HAL_GPIO_TogglePin(GPIOC, GPIO_PIN_7);
						//HAL_Delay(50);
					}

				}
			}
		}
	}
	if (!found)
	{
		loadFailed = 1;
	}
	presetWaitingToLoad = 0;
	diskBusy = 0;
	return found;
}

static void writePresetToSDCard(int fileSize)
{
	__disable_irq();
	 for (int i = 0; i < AUDIO_BUFFER_SIZE; i++)
	 {
		 audioOutBuffer[i] = 0;
	 }
	if(BSP_SD_IsDetected())
	{
		//if(f_mount(&SDFatFS,  SDPath, 1) == FR_OK)
		{
			//if(res == FR_OK)
			{
				diskBusy = 1;
				//make sure the number is not above 2 digits
			    if (presetNumberToSave > 99)
			    {
			        presetNumberToSave = 99;
			    }

				//turn the integer value into a 2 digit string
				char charBuf[10];
				char finalString[10];
				itoa(presetNumberToSave, charBuf, 10);
				int len = ((strlen(charBuf)));
				if (len == 1)
				{
					finalString[2] = charBuf[1];
					finalString[1] = charBuf[0];
					finalString[0] = '0';
					strcat(finalString, ".ebp");
				}

				else
				{
					strcat(charBuf, ".ebp");
					strcpy(finalString, charBuf);
				}

				if(f_open(&SDFile, finalString, FA_CREATE_ALWAYS | FA_WRITE) == FR_OK)
				{
					unsigned int bytesRead;
					f_write(&SDFile, &buffer, fileSize, &bytesRead);
					f_close(&SDFile);
				}

			}
			//f_mount(0, "", 0); //unmount
		}
	}
	presetWaitingToWrite = 0;
	diskBusy = 0;
	__enable_irq();
}

static int checkForSDCardTuning(uint8_t numberToLoad)
{
	int found = 0;
	if(BSP_SD_IsDetected())
	{
		diskBusy = 1;
		loadFailed = 0;
		//HAL_Delay(300);

		disk_initialize(0);

	    disk_status(0);

		if(f_mount(&SDFatFS,  SDPath, 1) == FR_OK)
		{

			FRESULT res;
			/* Start to search for preset files */
			char charBuf[10];
			char finalString[10];

			//turn the integer value into a 2 digit string

			itoa(numberToLoad, charBuf, 10);
			int len = ((strlen(charBuf)));
			if (len == 1)
			{
				finalString[2] = charBuf[1];
				finalString[1] = charBuf[0];
				finalString[0] = '0';
				strcat(finalString, ".ebt");
			}

			else
			{
				strcat(charBuf, ".ebt");
				strcpy(finalString, charBuf);
			}

			res = f_findfirst(&dir, &fno, SDPath, finalString);
			unsigned int bytesRead;
			if(res == FR_OK)
			{
				if(f_open(&SDFile, fno.fname, FA_OPEN_ALWAYS | FA_READ) == FR_OK)
				{
					f_read(&SDFile, &buffer, f_size(&SDFile), &bytesRead);
					tuningWaitingToParse = bytesRead;
					f_close(&SDFile);
					found = 1;
					for (int i = 0; i < 4; i++)
					{
						//HAL_GPIO_TogglePin(GPIOC, GPIO_PIN_7);
						//HAL_Delay(50);
					}

				}
			}
		}
	}
	if (!found)
	{
		loadFailed = 1;
	}
	tuningWaitingToLoad = 0;
	diskBusy = 0;
	return found;
}

static void writeTuningToSDCard(int fileSize)
{
	__disable_irq();
	 for (int i = 0; i < AUDIO_BUFFER_SIZE; i++)
	 {
		 audioOutBuffer[i] = 0;
	 }
	if(BSP_SD_IsDetected())
	{
		//if(f_mount(&SDFatFS,  SDPath, 1) == FR_OK)
		{
			//if(res == FR_OK)
			{
				diskBusy = 1;
				//make sure the number is not above 2 digits
			    if (tuningNumberToSave > 99)
			    {
			    	tuningNumberToSave = 99;
			    }

				//turn the integer value into a 2 digit string
				char charBuf[10];
				char finalString[10];
				itoa(tuningNumberToSave, charBuf, 10);
				int len = ((strlen(charBuf)));
				if (len == 1)
				{
					finalString[2] = charBuf[1];
					finalString[1] = charBuf[0];
					finalString[0] = '0';
					strcat(finalString, ".ebt");
				}

				else
				{
					strcat(charBuf, ".ebt");
					strcpy(finalString, charBuf);
				}

				if(f_open(&SDFile, finalString, FA_CREATE_ALWAYS | FA_WRITE) == FR_OK)
				{
					unsigned int bytesRead;
					f_write(&SDFile, &buffer, fileSize, &bytesRead);
					f_close(&SDFile);
				}

			}
			//f_mount(0, "", 0); //unmount
		}
	}
	tuningWaitingToWrite = 0;
	diskBusy = 0;
	__enable_irq();
}

uint8_t BSP_SD_IsDetected(void)
{
  __IO uint8_t status = SD_PRESENT;

  //if (BSP_PlatformIsDetected() == 0x0) // TODO: shouldn't be not!!!
  {
    //status = SD_NOT_PRESENT;
  }

  return status;
}

#define SDRAM_MODEREG_BURST_LENGTH_2 ((1 << 0))
#define SDRAM_MODEREG_BURST_LENGTH_4 ((1 << 1))

#define SDRAM_MODEREG_BURST_TYPE_SEQUENTIAL ((0 << 3))

#define SDRAM_MODEREG_CAS_LATENCY_3 ((1 << 4) | (1 << 5))

#define SDRAM_MODEREG_OPERATING_MODE_STANDARD ()

#define SDRAM_MODEREG_WRITEBURST_MODE_SINGLE ((1 << 9))
#define SDRAM_MODEREG_WRITEBURST_MODE_PROG_BURST ((0 << 9))

void SDRAM_init()
{
	    	FMC_SDRAM_CommandTypeDef Command;

	        __IO uint32_t tmpmrd = 0;
	        /* Step 3:  Configure a clock configuration enable command */
	        Command.CommandMode            = FMC_SDRAM_CMD_CLK_ENABLE;
	        Command.CommandTarget          = FMC_SDRAM_CMD_TARGET_BANK1;
	        Command.AutoRefreshNumber      = 1;
	        Command.ModeRegisterDefinition = 0;

	        /* Send the command */
	        HAL_SDRAM_SendCommand(&hsdram1, &Command, 0x1000);

	        /* Step 4: Insert 100 ms delay */
	        HAL_Delay(100);

	        /* Step 5: Configure a PALL (precharge all) command */
	        Command.CommandMode            = FMC_SDRAM_CMD_PALL;
	        Command.CommandTarget          = FMC_SDRAM_CMD_TARGET_BANK1;
	        Command.AutoRefreshNumber      = 1;
	        Command.ModeRegisterDefinition = 0;

	        /* Send the command */
	        HAL_SDRAM_SendCommand(&hsdram1, &Command, 0x1000);

	        /* Step 6 : Configure a Auto-Refresh command */
	        Command.CommandMode            = FMC_SDRAM_CMD_AUTOREFRESH_MODE;
	        Command.CommandTarget          = FMC_SDRAM_CMD_TARGET_BANK1;
	        Command.AutoRefreshNumber      = 4;
	        Command.ModeRegisterDefinition = 0;

	        /* Send the command */
	        HAL_SDRAM_SendCommand(&hsdram1, &Command, 0x1000);

	        /* Step 7: Program the external memory mode register */
	        tmpmrd = (uint32_t)SDRAM_MODEREG_BURST_LENGTH_4
	                 | SDRAM_MODEREG_BURST_TYPE_SEQUENTIAL | SDRAM_MODEREG_CAS_LATENCY_3
	                 | SDRAM_MODEREG_WRITEBURST_MODE_SINGLE;
	        //SDRAM_MODEREG_OPERATING_MODE_STANDARD | // Used in example, but can't find reference except for "Test Mode"

	        Command.CommandMode            = FMC_SDRAM_CMD_LOAD_MODE;
	        Command.CommandTarget          = FMC_SDRAM_CMD_TARGET_BANK1;
	        Command.AutoRefreshNumber      = 1;
	        Command.ModeRegisterDefinition = tmpmrd;

	        /* Send the command */
	        HAL_SDRAM_SendCommand(&hsdram1, &Command, 0x1000);

	        //HAL_SDRAM_ProgramRefreshRate(hsdram, 0x56A - 20);
	        HAL_SDRAM_ProgramRefreshRate(&hsdram1, 0x81A - 20);

}

void MPU_Conf(void)
{
	//code from Keshikan https://github.com/keshikan/STM32H7_DMA_sample
  //Thanks, Keshikan! This solves the issues with accessing the SRAM in the D2 area properly. -JS
	//should test the different possible settings to see what works best while avoiding needing to manually clear the cache -JS

	MPU_Region_InitTypeDef MPU_InitStruct;

	  HAL_MPU_Disable();

	  MPU_InitStruct.Enable = MPU_REGION_ENABLE;

	  //D2 Domain�SRAM1
	  MPU_InitStruct.BaseAddress = 0x30000000;
	  // Increased region size to 256k. In Keshikan's code, this was 512 bytes (that's all that application needed).
	  // Each audio buffer takes up the frame size * 8 (16 bits makes it *2 and stereo makes it *2 and double buffering makes it *2)
	  // So a buffer size for read/write of 4096 would take up 64k = 4096*8 * 2 (read and write).
	  // I increased that to 256k so that there would be room for the ADC knob inputs and other peripherals that might require DMA access.
	  // we have a total of 256k in SRAM1 (128k, 0x30000000-0x30020000) and SRAM2 (128k, 0x30020000-0x3004000) of D2 domain.
	  // There is an SRAM3 in D2 domain as well (32k, 0x30040000-0x3004800) that is currently not mapped by the MPU (memory protection unit) controller.

	  MPU_InitStruct.Size = MPU_REGION_SIZE_256KB;

	  MPU_InitStruct.AccessPermission = MPU_REGION_FULL_ACCESS;

	  //Shared Device
	  MPU_InitStruct.TypeExtField = MPU_TEX_LEVEL0;
	  MPU_InitStruct.IsCacheable = MPU_ACCESS_NOT_CACHEABLE;
	  MPU_InitStruct.IsBufferable = MPU_ACCESS_BUFFERABLE;
	  MPU_InitStruct.IsShareable = MPU_ACCESS_SHAREABLE;

	  //AN4838
//	  MPU_InitStruct.TypeExtField = MPU_TEX_LEVEL1;
//	  MPU_InitStruct.IsCacheable = MPU_ACCESS_NOT_CACHEABLE;
//	  MPU_InitStruct.IsBufferable = MPU_ACCESS_NOT_BUFFERABLE;
//	  MPU_InitStruct.IsShareable = MPU_ACCESS_NOT_SHAREABLE;

	  MPU_InitStruct.Number = MPU_REGION_NUMBER0;

	  MPU_InitStruct.SubRegionDisable = 0x00;

	  MPU_InitStruct.DisableExec = MPU_INSTRUCTION_ACCESS_DISABLE;

	  HAL_MPU_ConfigRegion(&MPU_InitStruct);

	  //now set up D3 domain RAM
	  MPU_InitStruct.Enable = MPU_REGION_ENABLE;
	  //D2 Domain�SRAM1
	  MPU_InitStruct.BaseAddress = 0x38000000;
	  MPU_InitStruct.Size = MPU_REGION_SIZE_64KB;
	  MPU_InitStruct.AccessPermission = MPU_REGION_FULL_ACCESS;
	  //AN4838
	  MPU_InitStruct.TypeExtField = MPU_TEX_LEVEL1;
	  MPU_InitStruct.IsCacheable = MPU_ACCESS_CACHEABLE;
	  MPU_InitStruct.IsBufferable = MPU_ACCESS_BUFFERABLE;
	  MPU_InitStruct.IsShareable = MPU_ACCESS_NOT_SHAREABLE;

	  MPU_InitStruct.Number = MPU_REGION_NUMBER1;

	  MPU_InitStruct.SubRegionDisable = 0x00;

	  MPU_InitStruct.DisableExec = MPU_INSTRUCTION_ACCESS_ENABLE;

	  HAL_MPU_ConfigRegion(&MPU_InitStruct);

	  MPU_InitStruct.Enable = MPU_REGION_ENABLE;

	  //BackupSRAM
	  MPU_InitStruct.BaseAddress = 0x38800000;
	  MPU_InitStruct.Size = MPU_REGION_SIZE_4KB;

	  MPU_InitStruct.AccessPermission = MPU_REGION_FULL_ACCESS;

	  MPU_InitStruct.TypeExtField = MPU_TEX_LEVEL0;
	  MPU_InitStruct.IsCacheable = MPU_ACCESS_NOT_CACHEABLE;
	  MPU_InitStruct.IsBufferable = MPU_ACCESS_NOT_BUFFERABLE;
	  MPU_InitStruct.IsShareable = MPU_ACCESS_SHAREABLE;

	  MPU_InitStruct.Number = MPU_REGION_NUMBER2;
	  MPU_InitStruct.SubRegionDisable = 0x00;
	  MPU_InitStruct.DisableExec = MPU_INSTRUCTION_ACCESS_DISABLE;
	  HAL_MPU_ConfigRegion(&MPU_InitStruct);

	  //SRAM for code execution not sure if TEX1 or TEX0 is better but probably doesn't matter because this memory is never written to, only read
	  MPU_InitStruct.Enable = MPU_REGION_ENABLE;
	  MPU_InitStruct.BaseAddress = 0x24000000;
	  MPU_InitStruct.Size = MPU_REGION_SIZE_512KB;

	  MPU_InitStruct.AccessPermission = MPU_REGION_FULL_ACCESS;

	  MPU_InitStruct.TypeExtField = MPU_TEX_LEVEL1;
	  MPU_InitStruct.IsCacheable = MPU_ACCESS_CACHEABLE;
	  MPU_InitStruct.IsBufferable = MPU_ACCESS_BUFFERABLE;
	  MPU_InitStruct.IsShareable = MPU_ACCESS_NOT_SHAREABLE;

	  MPU_InitStruct.Number = MPU_REGION_NUMBER3;
	  MPU_InitStruct.SubRegionDisable = 0x00;
	  MPU_InitStruct.DisableExec = MPU_INSTRUCTION_ACCESS_ENABLE;
	  HAL_MPU_ConfigRegion(&MPU_InitStruct);

	  //SDRAM as strongly ordered to avoid speculative fetches that might stall the external memory if interrupted
	  MPU_InitStruct.Enable = MPU_REGION_ENABLE;
	  MPU_InitStruct.BaseAddress = 0xc0000000;
	  MPU_InitStruct.Size = MPU_REGION_SIZE_64MB;

	  MPU_InitStruct.AccessPermission = MPU_REGION_FULL_ACCESS;

	  MPU_InitStruct.TypeExtField = MPU_TEX_LEVEL0;
	  MPU_InitStruct.IsCacheable = MPU_ACCESS_NOT_CACHEABLE;
	  MPU_InitStruct.IsBufferable = MPU_ACCESS_NOT_BUFFERABLE;
	  MPU_InitStruct.IsShareable = MPU_ACCESS_NOT_SHAREABLE;

	  MPU_InitStruct.Number = MPU_REGION_NUMBER4;
	  MPU_InitStruct.SubRegionDisable = 0x00;
	  MPU_InitStruct.DisableExec = MPU_INSTRUCTION_ACCESS_DISABLE;
	  HAL_MPU_ConfigRegion(&MPU_InitStruct);

	  //QSPI as strongly ordered to avoid speculative fetches that might stall the external memory if interrupted
	  MPU_InitStruct.Enable = MPU_REGION_ENABLE;
	  MPU_InitStruct.BaseAddress = 0x90040000;
	  MPU_InitStruct.Size = MPU_REGION_SIZE_64MB;

	  MPU_InitStruct.AccessPermission = MPU_REGION_FULL_ACCESS;

	  MPU_InitStruct.TypeExtField = MPU_TEX_LEVEL0;
	  MPU_InitStruct.IsCacheable = MPU_ACCESS_NOT_CACHEABLE;
	  MPU_InitStruct.IsBufferable = MPU_ACCESS_NOT_BUFFERABLE;
	  MPU_InitStruct.IsShareable = MPU_ACCESS_NOT_SHAREABLE;

	  MPU_InitStruct.Number = MPU_REGION_NUMBER5;
	  MPU_InitStruct.SubRegionDisable = 0x00;
	  MPU_InitStruct.DisableExec = MPU_INSTRUCTION_ACCESS_DISABLE;
	  HAL_MPU_ConfigRegion(&MPU_InitStruct);

	  HAL_MPU_Enable(MPU_PRIVILEGED_DEFAULT);
}

void __ATTR_ITCMRAM handleSPI (uint8_t offset)
{
	interruptChecker = 1;
	// if the first number is a 1 then it's a midi note/ctrl/bend message
	if (SPI_RX[offset] == ReceivingMIDI)
	{

		 uint8_t currentByte = offset+1;

		 while ((SPI_RX[currentByte] != 0) && ((currentByte % 16) < SPI_FRAME_SIZE))
		 {
			 cStack_push(&midiStack,SPI_RX[currentByte],SPI_RX[currentByte+1],SPI_RX[currentByte+2]);
			 currentByte = currentByte+3;
		 }
		 //HAL_GPIO_WritePin(GPIOC, GPIO_PIN_7, GPIO_PIN_SET);
	}
	// if the first number is a 2 then it's a preset write
	else if (SPI_RX[offset] == ReceivingPreset)
	{
		//got a new preset to write to memory
		 //HAL_GPIO_TogglePin(GPIOC, GPIO_PIN_7);

		 //if you aren't already writing a preset to memory, start the process
		 if (writingState != ReceivingPreset)
		 {
			 writingState = ReceivingPreset; // set the flag to let the mcu know that a preset write is in progress
			 diskBusy = 1;
			 audioMasterLevel = 0.0f;
			 //write the raw data as a preset number on the SD card
			 bufferPos = 0;
		 }
		 presetNumberToSave = SPI_RX[offset + 1];
		 uint8_t currentByte = offset+2; // first number says what it is 2nd number says which number it is

		 for (int i = 0; i < 14; i++)
		 {
			 buffer[bufferPos++] = SPI_RX[currentByte + i];

		 }
		 //HAL_GPIO_WritePin(GPIOC, GPIO_PIN_7, GPIO_PIN_RESET);
	}
	else if (SPI_RX[offset] == ReceivingTuning)
	{
		//if you aren't already writing a tuning to memory, start the process
		 if (writingState != ReceivingTuning)
		 {
			 writingState = ReceivingTuning; // set the flag to let the mcu know that a tuning write is in progress
			 diskBusy = 1;
			 audioMasterLevel = 0.0f;
			 //write the raw data as a tuning number on the SD card
			 bufferPos = 0;
		 }
		 tuningNumberToSave = SPI_RX[offset + 1];
		 uint8_t currentByte = offset+2; // first number says what it is 2nd number says which number it is

		 for (int i = 0; i < 14; i++)
		 {
			 buffer[bufferPos++] = SPI_RX[currentByte + i];

		 }
	}
	else if (SPI_RX[offset] == ReceivingEnd)
	{
		if(writingState == ReceivingPreset)
		{
			 writingState = 0;
			 presetNumberToLoad = presetNumberToSave;
			 /* Parse into Audio Params */
			 presetWaitingToParse = bufferPos;
			 presetWaitingToWrite = bufferPos;
		} else if (writingState == ReceivingTuning)
		{
			writingState = 0;
			if (tuningNumberToSave == 0)
			{
				return;
			}
			tuningNumberToLoad = tuningNumberToSave;
			tuningWaitingToParse = bufferPos;
			tuningWaitingToWrite = bufferPos;
		}
	}

	else if (SPI_RX[offset] == LoadingPreset)
	{
		uint8_t loadNumber = SPI_RX[offset+1];
		if (loadNumber < MAX_NUM_PRESETS)
		{
			presetNumberToLoad = loadNumber;
			whichPresetToSendName = loadNumber;
			presetWaitingToLoad = 1;
		}
	}

	else if (SPI_RX[offset] == LoadingTuning)
	{
		uint8_t loadNumber = SPI_RX[offset+1];
		if (loadNumber == 0)
		{
			for (int i = 0; i < 128; i++)
			{
				fractionalMidi[i] =  (float)i; //12-TET
			}
		}
		if (loadNumber < MAX_NUM_TUNINGS)
		{
			tuningNumberToLoad = loadNumber;
			whichTuningToSendName = loadNumber;
			tuningWaitingToLoad = 1;
		}
	}

	if (sendPresetName)
	{
		SPI_TX[offset] = 253; //special byte that says this is a preset name;
		SPI_TX[offset+1] = whichPresetToSendName;
		SPI_TX[offset+2] = presetNamesArray[whichPresetToSendName][0];
		SPI_TX[offset+3] = presetNamesArray[whichPresetToSendName][1];
		SPI_TX[offset+4] = presetNamesArray[whichPresetToSendName][2];
		SPI_TX[offset+5] = presetNamesArray[whichPresetToSendName][3];
		SPI_TX[offset+6] = presetNamesArray[whichPresetToSendName][4];
		SPI_TX[offset+7] = presetNamesArray[whichPresetToSendName][5];
		SPI_TX[offset+8] = presetNamesArray[whichPresetToSendName][6];
		SPI_TX[offset+9] = presetNamesArray[whichPresetToSendName][7];
		SPI_TX[offset+10] = presetNamesArray[whichPresetToSendName][8];
		SPI_TX[offset+11] = presetNamesArray[whichPresetToSendName][9];
		SPI_TX[offset+12] = presetNamesArray[whichPresetToSendName][10];
		SPI_TX[offset+13] = presetNamesArray[whichPresetToSendName][11];
		SPI_TX[offset+14] = presetNamesArray[whichPresetToSendName][12];
		SPI_TX[offset+15] = presetNamesArray[whichPresetToSendName][13];
		whichPresetToSendName = (whichPresetToSendName + 1) % MAX_NUM_PRESETS;
	}

	else
	{
		SPI_TX[offset] = 254; //special byte that says this is a preset name;
		SPI_TX[offset+1] = whichTuningToSendName;
		SPI_TX[offset+2] = tuningNamesArray[whichTuningToSendName][0];
		SPI_TX[offset+3] = tuningNamesArray[whichTuningToSendName][1];
		SPI_TX[offset+4] = tuningNamesArray[whichTuningToSendName][2];
		SPI_TX[offset+5] = tuningNamesArray[whichTuningToSendName][3];
		SPI_TX[offset+6] = tuningNamesArray[whichTuningToSendName][4];
		SPI_TX[offset+7] = tuningNamesArray[whichTuningToSendName][5];
		SPI_TX[offset+8] = tuningNamesArray[whichTuningToSendName][6];
		SPI_TX[offset+9] = tuningNamesArray[whichTuningToSendName][7];
		SPI_TX[offset+10] = tuningNamesArray[whichTuningToSendName][8];
		SPI_TX[offset+11] = tuningNamesArray[whichTuningToSendName][9];
		SPI_TX[offset+12] = tuningNamesArray[whichTuningToSendName][10];
		SPI_TX[offset+13] = tuningNamesArray[whichTuningToSendName][11];
		SPI_TX[offset+14] = tuningNamesArray[whichTuningToSendName][12];
		SPI_TX[offset+15] = tuningNamesArray[whichTuningToSendName][13];
		whichTuningToSendName = (whichTuningToSendName + 1) % MAX_NUM_TUNINGS;
	}
	sendPresetName = !sendPresetName;

}

float __ATTR_ITCMRAM scaleDefault(float input)
{
	input = LEAF_clip(0.f, input, 1.f);
	return input;
}

float __ATTR_ITCMRAM scaleTwo(float input)
{
	input = LEAF_clip(0.f, input, 1.f);
	return (input * 2.0f);
}

float __ATTR_ITCMRAM scaleOscPitch(float input)
{
	//input = LEAF_clip(0.0f, input, 1.0f);
	return (input * 48.0f) - 24.0f;
}

float __ATTR_ITCMRAM scaleOscHarmonics(float input)
{
	//input = LEAF_clip(0.0f, input, 1.0f);
	return (input * 34.0f) - 17.0f; // fix this when adjusting the plugin - should be 32 and +/-16 but that's not what the plugin sends right now
}

float __ATTR_ITCMRAM scaleOscFine(float input)
{
	//input = LEAF_clip(0.0f, input, 1.f);
	return (input * 200.0f) - 100.0f;
}

float __ATTR_ITCMRAM scaleOscFreq(float input)
{
	//input = LEAF_clip(0.f, input, 1.f);
	return (input * 4000.0f) - 2000.0f;
}

float __ATTR_ITCMRAM scaleTranspose(float input)
{
	input = LEAF_clip(0.0f, input, 1.f);
	return (input * 96.0f) - 48.0f;
}

float __ATTR_ITCMRAM scalePitchBend(float input)
{
	input = LEAF_clip(0.f, input, 1.f);
	return (input * 48.0f);
}

float __ATTR_ITCMRAM scaleFilterCutoff(float input)
{
	//input = LEAF_clip(0.f, input, 1.f);
	return (input * 127.0f);
}

float __ATTR_ITCMRAM scaleFilterResonance(float input)
{
	//lookup table for filter res
	input = LEAF_clip(0.1f, input, 1.0f);
	//scale to lookup range
	input *= 2047.0f;
	int inputInt = (int)input;
	float inputFloat = (float)inputInt - input;
	int nextPos = LEAF_clip(0, inputInt + 1, 2047);
	return LEAF_clip(0.1f, (resTable[inputInt] * (1.0f - inputFloat)) + (resTable[nextPos] * inputFloat), 10.0f);
	//return
}

float __ATTR_ITCMRAM scaleEnvTimes(float input)
{
	//lookup table for env times
	input = LEAF_clip(0.0f, input, 1.0f);
	//scale to lookup range
	input *= 2047.0f;
	int inputInt = (int)input;
	float inputFloat = (float)inputInt - input;
	int nextPos = LEAF_clip(0, inputInt + 1, 2047);
	return (envTimeTable[inputInt] * (1.0f - inputFloat)) + (envTimeTable[nextPos] * inputFloat);

	//return
}

float __ATTR_ITCMRAM scaleLFORates(float input)
{
	//lookup table for LFO rates
	input = LEAF_clip(0.0f, input, 1.0f);
	//scale to lookup range
	input *= 2047.0f;
	int inputInt = (int)input;
	float inputFloat = (float)inputInt - input;
	int nextPos = LEAF_clip(0, inputInt + 1, 2047);
	return (lfoRateTable[inputInt] * (1.0f - inputFloat)) + (lfoRateTable[nextPos] * inputFloat);
	//return
}

float __ATTR_ITCMRAM scaleFinalLowpass(float input)
{
	//input = LEAF_clip(0.f, input, 1.f);
	return ((input * 70.0f) + 58.0f);
}

void blankFunction(float a, int b)
{
	;
}

void __ATTR_ITCMRAM parseTuning(int size, int tuningNumber)
{
	//turn off the volume while changing parameters
	 __disable_irq();
	 //for (int i = 0; i < AUDIO_BUFFER_SIZE; i++)
	 {
		 //audioOutBuffer[i] = 0;
	 }
	//audioMasterLevel = 0.0f;
	//osc params

	uint16_t bufferIndex = 0;
	//read first element in buffer as a count of how many parameters
	//uint16_t paramCount = (buffer[0] << 8) + buffer[1];
	if (size > 280)
	{
		//error in transmission - give up and don't parse!
		//audioMasterLevel = 1.0f;
		tuningWaitingToParse = 0;
		__enable_irq();
		return;
	}

	//check the validity of the transfer by verifying that the param array and mapping arrays both end with the required 0xefef values
	uint16_t paramEndCheck = (buffer[270] << 8) + buffer[271];
	if (paramEndCheck != 0xefef)
	{
		//error in transmission - give up and don't parse!
		//audioMasterLevel = 1.0f;
		tuningWaitingToParse = 0;
		__enable_irq();
		return;
	}

	//read first 14 items in buffer as the 14 character string that is the name of the preset
	for (int i = 0; i < 14; i++)
	{
		tuningName[i] = buffer[bufferIndex];
		tuningNamesArray[tuningNumber][i] = buffer[bufferIndex];
		bufferIndex++;
	}
	//bufferIndex = 2;
	//now read the fractional midi
	for (int i = 0; i < 128; i++)
	{
		fractionalMidi[i] =  ((buffer[bufferIndex] << 8) + buffer[bufferIndex+1]) * 0.001953125f; // divide by 512.f

		bufferIndex += 2;
	}
	tuningWaitingToParse = 0;
	//audioMasterLevel = 1.0f;
	diskBusy = 0;
	__enable_irq();
}

void __ATTR_ITCMRAM parsePreset(int size, int presetNumber)
{
	//turn off the volume while changing parameters
	 __disable_irq();
	 for (int i = 0; i < AUDIO_BUFFER_SIZE; i++)
	 {
		 audioOutBuffer[i] = 0;
	 }
	audioMasterLevel = 0.0f;
	//osc params

	uint16_t bufferIndex = 0;

	//read first 14 items in buffer as the 14 character string that is the name of the preset
	for (int i = 0; i < 14; i++)
	{
		presetName[i] = buffer[bufferIndex];
		presetNamesArray[presetNumber][i] = buffer[bufferIndex];
		bufferIndex++;
	}

	//skip the macro names (don't need them on electrobass)
	bufferIndex = bufferIndex + (8*14);

	//read first element in buffer (after the 14 character preset name and macro names) as a count of how many parameters
	uint16_t paramCount = (buffer[bufferIndex] << 8) + buffer[bufferIndex+1];
	if (paramCount > size)
	{
		//error in transmission - give up and don't parse!
		audioMasterLevel = 1.0f;
		presetWaitingToParse = 0;
		__enable_irq();
		return;
	}
	//check the validity of the transfer by verifying that the param array and mapping arrays both end with the required 0xefef values
	//should make this a real checksum
	uint16_t paramEndCheck = (buffer[paramCount*2+bufferIndex+2] << 8) + buffer[paramCount*2+bufferIndex+3];
	if (paramEndCheck != 0xefef)
	{
		//error in transmission - give up and don't parse!
		audioMasterLevel = 1.0f;
		presetWaitingToParse = 0;
		__enable_irq();
		return;
	}
	uint16_t mappingCount = (buffer[paramCount*2+bufferIndex+4] << 8) + buffer[paramCount*2+bufferIndex+5];

	//20 is the 6 bytes plus the 14 characters
	//paramCount is * 2 because they are 2 bytes per param, mappingCount * 5 because they are 5 bytes per mapping
	uint16_t mappingEndLocation = (paramCount * 2) + (mappingCount * 5) + bufferIndex+6;

	if (mappingEndLocation > size)
	{
		//error in transmission - give up and don't parse!
		audioMasterLevel = 1.0f;
		presetWaitingToParse = 0;
		__enable_irq();
		return;
	}

	uint16_t mappingEndCheck = (buffer[mappingEndLocation] << 8) + buffer[mappingEndLocation+1];
	if (mappingEndCheck != 0xfefe) //this check value is 0xfefe
	{
		//error in transmission - give up and don't parse!
		audioMasterLevel = 1.0f;
		presetWaitingToParse = 0;
		__enable_irq();
		return;
	}

	 //move past the paramcount position in the buffer to start parsing the parameter data
	bufferIndex = bufferIndex + 2;

	//now read the parameters
	for (int i = 0; i < paramCount; i++)
	{
		params[i].zeroToOneVal = INV_TWO_TO_16 * ((buffer[bufferIndex] << 8) + buffer[bufferIndex+1]);

		//need to map all of the params to their scaled parameters and set them to the realVals
		params[i].scaleFunc = &scaleDefault;

		//blank function means that it doesn't actually set a final value, we will read directly from the realVals when we need it
		params[i].setParam = &blankFunction;

		bufferIndex += 2;
	}

	//if loading old presets that don't have as many params, blank out the empty slots
	for (int i = paramCount; i < NUM_PARAMS; i++)
	{
		params[i].zeroToOneVal = 0.0f;
		params[i].scaleFunc = &scaleDefault;
		params[i].setParam = &blankFunction;
	}

	//params[Master].scaleFunc = &scaleTwo;
	params[Transpose].scaleFunc = &scaleTranspose;
	params[PitchBendRange].scaleFunc = &scalePitchBend;
	//params[NoiseAmp].scaleFunc = &scaleTwo;
	params[Osc1Pitch].scaleFunc = &scaleOscPitch;
	params[Osc1Fine].scaleFunc = &scaleOscFine;
	params[Osc1Freq].scaleFunc = &scaleOscFreq;
	//params[Osc1Amp].scaleFunc = &scaleTwo;
	params[Osc1Harmonics].scaleFunc = &scaleOscHarmonics;
	params[Osc2Pitch].scaleFunc = &scaleOscPitch;
	params[Osc2Fine].scaleFunc = &scaleOscFine;
	params[Osc2Freq].scaleFunc = &scaleOscFreq;
	//params[Osc2Amp].scaleFunc = &scaleTwo;
	params[Osc2Harmonics].scaleFunc = &scaleOscHarmonics;
	params[Osc3Pitch].scaleFunc = &scaleOscPitch;
	params[Osc3Fine].scaleFunc = &scaleOscFine;
	params[Osc3Freq].scaleFunc = &scaleOscFreq;
	//params[Osc3Amp].scaleFunc = &scaleTwo;
	params[Osc3Harmonics].scaleFunc = &scaleOscHarmonics;
	params[Filter1Cutoff].scaleFunc = &scaleFilterCutoff;
	params[Filter1Resonance].scaleFunc = &scaleFilterResonance;
	params[Filter2Cutoff].scaleFunc = &scaleFilterCutoff;
	params[Filter2Resonance].scaleFunc = &scaleFilterResonance;
	params[Envelope1Attack].scaleFunc = &scaleEnvTimes;
	params[Envelope1Decay].scaleFunc = &scaleEnvTimes;
	params[Envelope1Release].scaleFunc = &scaleEnvTimes;
	params[Envelope2Attack].scaleFunc = &scaleEnvTimes;
	params[Envelope2Decay].scaleFunc = &scaleEnvTimes;
	params[Envelope2Release].scaleFunc = &scaleEnvTimes;
	params[Envelope3Attack].scaleFunc = &scaleEnvTimes;
	params[Envelope3Decay].scaleFunc = &scaleEnvTimes;
	params[Envelope3Release].scaleFunc = &scaleEnvTimes;
	params[Envelope4Attack].scaleFunc = &scaleEnvTimes;
	params[Envelope4Decay].scaleFunc = &scaleEnvTimes;
	params[Envelope4Release].scaleFunc = &scaleEnvTimes;
	params[LFO1Rate].scaleFunc = &scaleLFORates;
	params[LFO2Rate].scaleFunc = &scaleLFORates;
	params[LFO3Rate].scaleFunc = &scaleLFORates;
	params[LFO4Rate].scaleFunc = &scaleLFORates;
	//params[OutputAmp].scaleFunc = &scaleTwo;
	params[OutputTone].scaleFunc  = &scaleFinalLowpass;
	for (int i = 0; i < NUM_EFFECT; i++)
		{
			FXType effectType = roundf(params[Effect1FXType + (EffectParamsNum * i)].realVal * (NUM_EFFECT_TYPES-1));
			param *FXAlias = &params[Effect1Param1 + (EffectParamsNum*i)];

				if (effectType > FXLowpass)
				{
					FXAlias[2].scaleFunc = &scaleFilterResonance;
				}

		}
	for (int i = 0; i < NUM_PARAMS; i++)
	{
		params[i].realVal = params[i].scaleFunc(params[i].zeroToOneVal);
	}

	uint8_t enabledCount = 0;

	for (int i = 0; i < NUM_OSC; i++)
	{
		int oscshape = roundf(params[Osc1ShapeSet + (OscParamsNum * i)].realVal * (NUM_OSC_SHAPES-1));
		switch (oscshape)
		{
			  case 0:
				  shapeTick[i] = &sawSquareTick;
				  break;
			  case 1:
				  shapeTick[i] = &sineTriTick;
				  break;
			  case 2:
				  shapeTick[i] = &sawTick;
				  break;
			  case 3:
				  shapeTick[i] = &pulseTick;
				  break;
			  case 4:
				  shapeTick[i] = &sineTick;
				  break;
			  case 5:
				  shapeTick[i] = &triTick;
				  break;
			  case 6:
				  shapeTick[i] = &userTick;
				  break;
			  default:
				  break;
		}
		if (params[Osc1 + (OscParamsNum * i)].realVal  > 0.5f)
		{
			enabledCount++;
		}
	}
	//set amplitude of oscillators based on how many are enabled
	oscAmpMult = oscAmpMultArray[enabledCount];

	for (int i = 0; i < NUM_FILT; i++)
	{
		int filterType = roundf(params[Filter1Type + (i * FilterParamsNum)].realVal * (NUM_FILTER_TYPES-1));
		switch (filterType)
		{
			  case 0:
				  filterTick[i] = &lowpassTick;
				  filterSetters[i].setQ = &lowpassSetQ;
				  filterSetters[i].setGain = &lowpassSetGain;
				  break;
			  case 1:
				  filterTick[i] = &highpassTick;
				  filterSetters[i].setQ = &highpassSetQ;
				  filterSetters[i].setGain = &highpassSetGain;
				  break;
			  case 2:
				  filterTick[i] = &bandpassTick;
				  filterSetters[i].setQ = &bandpassSetQ;
				  filterSetters[i].setGain = &bandpassSetGain;
				  break;
			  case 3:
				  filterTick[i] = &diodeLowpassTick;
				  filterSetters[i].setQ = &diodeLowpassSetQ;
				  filterSetters[i].setGain = &diodeLowpassSetGain;
				  break;
			  case 4:
				  filterTick[i] = &VZpeakTick;
				  filterSetters[i].setQ = &VZpeakSetQ;
				  filterSetters[i].setGain = &VZpeakSetGain;
				  break;
			  case 5:
				  filterTick[i] = &VZlowshelfTick;
				  filterSetters[i].setQ = &VZlowshelfSetQ;
				  filterSetters[i].setGain = &VZlowshelfSetGain;
				  break;
			  case 6:
				  filterTick[i] = &VZhighshelfTick;
				  filterSetters[i].setQ = &VZhighshelfSetQ;
				  filterSetters[i].setGain = &VZhighshelfSetGain;
				  break;
			  case 7:
				  filterTick[i] = &VZbandrejectTick;
				  filterSetters[i].setQ = &VZbandrejectSetQ;
				  filterSetters[i].setGain = &VZbandrejectSetGain;
				  break;
			  case 8:
				  filterTick[i] = &LadderLowpassTick;
				  filterSetters[i].setQ = &LadderLowpassSetQ;
				  filterSetters[i].setGain = &LadderLowpassSetGain;
				  break;
			  default:
				  break;
		}
	}

	for (int i = 0; i < NUM_LFOS; i++)
	{
		int LFOType = roundf(params[LFO1ShapeSet + (i * LFOParamsNum)].realVal * (NUM_LFO_SHAPES-1));
		switch(LFOType)
		{
			case SineTriLFOShapeSet:
				lfoShapeTick[i] = &lfoSineTriTick;
				lfoSetters[i].setRate = &lfoSineTriSetRate;
				lfoSetters[i].setShape = &lfoSineTriSetShape;
				lfoSetters[i].setPhase = &lfoSineTriSetPhase;
				break;
			case SawPulseLFOShapeSet:
				lfoShapeTick[i] = &lfoSawSquareTick;
				lfoSetters[i].setRate = &lfoSawSquareSetRate;
				lfoSetters[i].setShape = &lfoSawSquareSetShape;
				lfoSetters[i].setPhase = &lfoSawSquareSetPhase;
				break;
			case SineLFOShapeSet:
				lfoShapeTick[i] = &lfoSineTick;
				lfoSetters[i].setRate = &lfoSineSetRate;
				lfoSetters[i].setShape = &lfoSineSetShape;
				lfoSetters[i].setPhase = &lfoSineSetPhase;
				break;
			case TriLFOShapeSet:
				lfoShapeTick[i] = &lfoTriTick;
				lfoSetters[i].setRate = &lfoTriSetRate;
				lfoSetters[i].setShape = &lfoTriSetShape;
				lfoSetters[i].setPhase = &lfoTriSetPhase;
				break;
			case SawLFOShapeSet:
				lfoShapeTick[i] = &lfoSawTick;
				lfoSetters[i].setRate = &lfoSawSetRate;
				lfoSetters[i].setShape = &lfoSawSetShape;
				lfoSetters[i].setPhase = &lfoSawSetPhase;
				break;
			case PulseLFOShapeSet:
				lfoShapeTick[i] = &lfoPulseTick;
				lfoSetters[i].setRate = &lfoPulseSetRate;
				lfoSetters[i].setShape = &lfoPulseSetShape;
				lfoSetters[i].setPhase = &lfoPulseSetPhase;
				break;
		}
	}

	for (int i = 0; i < NUM_EFFECT; i++)
	{
		FXType effectType = roundf(params[Effect1FXType + (EffectParamsNum * i)].realVal * (NUM_EFFECT_TYPES-1));
		switch (effectType)
		{
			  case None:
				  effectTick[i] = &blankTick;
				  effectSetters[i].setParam1 = &blankFunction;
				  effectSetters[i].setParam2 = &blankFunction;
				  effectSetters[i].setParam3 = &blankFunction;
				  effectSetters[i].setParam4 = &blankFunction;
				  effectSetters[i].setParam5 = &blankFunction;
				  break;
			  case Softclip:
				  effectTick[i] = &softClipTick;
				  effectSetters[i].setParam1 = &clipperGainSet;
				  effectSetters[i].setParam2 = &offsetParam2;
				  effectSetters[i].setParam3 = &param3Soft;
				  effectSetters[i].setParam4 = &param4Linear;
				  effectSetters[i].setParam5 = &blankFunction;
				  break;
			  case Hardclip:
				  effectTick[i] = &hardClipTick;
				  effectSetters[i].setParam1 = &clipperGainSet;
				  effectSetters[i].setParam2 = &offsetParam2;
				  effectSetters[i].setParam3 = &param3Hard;
				  effectSetters[i].setParam4 = &param4Linear;
				  effectSetters[i].setParam5 = &blankFunction;
				  break;
			  case ABSaturator:
				  effectTick[i] = &satTick;
				  effectSetters[i].setParam1 = &clipperGainSet;
				  effectSetters[i].setParam2 = &offsetParam2;
				  effectSetters[i].setParam3 = &param3Linear;
				  effectSetters[i].setParam4 = &param4Linear;
				  effectSetters[i].setParam5 = &blankFunction;
				  break;
			  case Tanh:
				  effectTick[i] = &tanhTick;
				  effectSetters[i].setParam1 = &clipperGainSet;
				  effectSetters[i].setParam2 = &offsetParam2;
				  effectSetters[i].setParam3 = &param3Linear;
				  effectSetters[i].setParam4 = &param4Linear;
				  effectSetters[i].setParam5 = &blankFunction;
				  break;
			  case Shaper:
				  effectTick[i] = &shaperTick;
				  effectSetters[i].setParam1 = &clipperGainSet;
				  effectSetters[i].setParam2 = &offsetParam2;
				  effectSetters[i].setParam3 = &param3Linear;
				  effectSetters[i].setParam4 = &param4Linear;
				  effectSetters[i].setParam5 = &blankFunction;
				  break;
			  case Compressor:
				  effectTick[i] = &compressorTick;
				  effectSetters[i].setParam1 = &compressorParam1;
				  effectSetters[i].setParam2 = &compressorParam2;
				  effectSetters[i].setParam3 = &compressorParam3;
				  effectSetters[i].setParam4 = &compressorParam4;
				  effectSetters[i].setParam5 = &compressorParam5;
				  break;
			  case Chorus:
				  effectTick[i] = &chorusTick;
				  effectSetters[i].setParam1 = &chorusParam1;
				  effectSetters[i].setParam2 = &chorusParam2;
				  effectSetters[i].setParam3 = &chorusParam3;
				  effectSetters[i].setParam4 = &chorusParam4;
				  effectSetters[i].setParam5 = &blankFunction;
				  break;
			  case Bitcrush:
				  effectTick[i] = &bcTick;
				  effectSetters[i].setParam1 = &clipperGainSet;
				  effectSetters[i].setParam2 = &param2Linear;
				  effectSetters[i].setParam3 = &param3BC;
				  effectSetters[i].setParam4 = &param4Linear;
				  effectSetters[i].setParam5 = &param5Linear;
				  break;
			  case TiltFilter:
				  effectTick[i] = &tiltFilterTick;
				  effectSetters[i].setParam1 = &tiltParam1;
				  effectSetters[i].setParam2 = &tiltParam2;
				  effectSetters[i].setParam3 = &tiltParam3;
				  effectSetters[i].setParam4 = &tiltParam4;
				  effectSetters[i].setParam5 = &param5Linear;
				  break;
			  case Wavefolder:
				  effectTick[i] = &wavefolderTick;
				  effectSetters[i].setParam1 = &wavefolderParam1;
				  effectSetters[i].setParam2 = &offsetParam2;
				  effectSetters[i].setParam3 = &wavefolderParam3;
				  effectSetters[i].setParam4 = &param4Linear;
				  effectSetters[i].setParam5 = &param5Linear;
				  break;
			  case FXLowpass :
				  effectTick[i] = &FXlowpassTick;
				  effectSetters[i].setParam1 = &FXLowpassParam1;
				  effectSetters[i].setParam2 = &blankFunction;
				  effectSetters[i].setParam3 = &FXLowpassParam3;
				  effectSetters[i].setParam4 = &blankFunction;;
				  effectSetters[i].setParam5 = &blankFunction;;
				  break;
			  case FXHighpass :
				  effectTick[i] = &FXhighpassTick;
				  effectSetters[i].setParam1 = &FXHighpassParam1;
				  effectSetters[i].setParam2 = &blankFunction;
				  effectSetters[i].setParam3 = &FXHighpassParam3;
				  effectSetters[i].setParam4 = &blankFunction;
				  effectSetters[i].setParam5 = &blankFunction;
				  break;
			  case FXBandpass :
				  effectTick[i] = &FXbandpassTick;
				  effectSetters[i].setParam1 = &FXBandpassParam1;
				  effectSetters[i].setParam2 = &blankFunction;
				  effectSetters[i].setParam3 = &FXBandpassParam3;
				  effectSetters[i].setParam4 = &blankFunction;
				  effectSetters[i].setParam5 = &blankFunction;
				  break;
			  case FXDiode :
				  effectTick[i] = &FXdiodeLowpassTick;
				  effectSetters[i].setParam1 = &FXDiodeParam1;
				  effectSetters[i].setParam2 = &blankFunction;
				  effectSetters[i].setParam3 = &FXDiodeParam3;
				  effectSetters[i].setParam4 = &blankFunction;
				  effectSetters[i].setParam5 = &blankFunction;
				  break;
			  case FXPeak :
				  effectTick[i] = &FXVZpeakTick;
				  effectSetters[i].setParam1 = &FXPeakParam1;
				  effectSetters[i].setParam2 = &FXPeakParam2;
				  effectSetters[i].setParam3 = &FXPeakParam3;
				  effectSetters[i].setParam4 = &blankFunction;
				  effectSetters[i].setParam5 = &blankFunction;
				  break;
			  case FXLowShelf :
				  effectTick[i] = &FXVZlowshelfTick;
				  effectSetters[i].setParam1 = &FXLowShelfParam1;
				  effectSetters[i].setParam2 = &FXLowShelfParam2;
				  effectSetters[i].setParam3 = &FXLowShelfParam3;
				  effectSetters[i].setParam4 = &blankFunction;
				  effectSetters[i].setParam5 = &blankFunction;
				  break;
			  case FXHighShelf :
				  effectTick[i] = FXVZhighshelfTick;
				  effectSetters[i].setParam1 = &FXHighShelfParam1;;
				  effectSetters[i].setParam2 = &FXHighShelfParam2;;
				  effectSetters[i].setParam3 = &FXHighShelfParam3;;
				  effectSetters[i].setParam4 = &blankFunction;;
				  effectSetters[i].setParam5 = &blankFunction;;
				  break;
			  case FXNotch :
				  effectTick[i] = FXVZbandrejectTick;
				  effectSetters[i].setParam1 = &FXNotchParam1;;
				  effectSetters[i].setParam2 = &FXNotchParam2;;
				  effectSetters[i].setParam3 = &FXNotchParam3;;
				  effectSetters[i].setParam4 = &blankFunction;;
				  effectSetters[i].setParam5 = &blankFunction;;
				  break;
			  case FXLadder :
				  effectTick[i] = &FXLadderLowpassTick;
				  effectSetters[i].setParam1 = &FXLadderParam1;;
				  effectSetters[i].setParam2 = &blankFunction;;
				  effectSetters[i].setParam3 = &FXLadderParam3;;
				  effectSetters[i].setParam4 = &blankFunction;;
				  effectSetters[i].setParam5 = &blankFunction;;
				  break;
			  default:
				  break;
		}
	}

	//noiseparams
	params[NoiseTilt].setParam = &noiseSetTilt;
	params[NoisePeakFreq].setParam = &noiseSetFreq;
	params[NoisePeakGain].setParam  = &noiseSetGain;
	///////Setters for paramMapping
	params[Master].setParam = &setMaster;
	params[Transpose].setParam = &setTranspose;
	params[PitchBendRange].setParam = &setPitchBendRange;
	params[OutputTone].setParam = &setFinalLowpass;

	//params[NoiseAmp].setParam = &setNoiseAmp;

	params[Osc1Pitch].setParam = &setFreqMultPitch;
	params[Osc2Pitch].setParam = &setFreqMultPitch;
	params[Osc3Pitch].setParam = &setFreqMultPitch;

	params[Osc1Harmonics].setParam = &setFreqMultHarm;
	params[Osc2Harmonics].setParam = &setFreqMultHarm;
	params[Osc3Harmonics].setParam = &setFreqMultHarm;

	params[Effect1Param1].setParam = effectSetters[0].setParam1;
	params[Effect1Param2].setParam = effectSetters[0].setParam2;
	params[Effect1Param3].setParam = effectSetters[0].setParam3;
	params[Effect1Param4].setParam = effectSetters[0].setParam4;
	params[Effect1Param5].setParam = effectSetters[0].setParam5;
	params[Effect1Mix].setParam = &fxMixSet;
	params[Effect1PostGain].setParam = &fxPostGainSet;
	params[Effect2Param1].setParam = effectSetters[1].setParam1;
	params[Effect2Param2].setParam = effectSetters[1].setParam2;
	params[Effect2Param3].setParam = effectSetters[1].setParam3;
	params[Effect2Param4].setParam = effectSetters[1].setParam4;
	params[Effect2Param5].setParam = effectSetters[1].setParam5;
	params[Effect2Mix].setParam = &fxMixSet;
	params[Effect2PostGain].setParam = &fxPostGainSet;
	params[Effect3Param1].setParam = effectSetters[2].setParam1;
	params[Effect3Param2].setParam = effectSetters[2].setParam2;
	params[Effect3Param3].setParam = effectSetters[2].setParam3;
	params[Effect3Param4].setParam = effectSetters[2].setParam4;
	params[Effect3Param5].setParam = effectSetters[2].setParam5;
	params[Effect3Mix].setParam = &fxMixSet;
	params[Effect3PostGain].setParam = &fxPostGainSet;
	params[Effect4Param1].setParam = effectSetters[3].setParam1;
	params[Effect4Param2].setParam = effectSetters[3].setParam2;
	params[Effect4Param3].setParam = effectSetters[3].setParam3;
	params[Effect4Param4].setParam = effectSetters[3].setParam4;
	params[Effect4Param5].setParam = effectSetters[3].setParam5;
	params[Effect4Mix].setParam = &fxMixSet;
	params[Effect4PostGain].setParam = &fxPostGainSet;
	params[Filter1Resonance].setParam = filterSetters[0].setQ;
	params[Filter1Gain].setParam = filterSetters[0].setGain;
	params[Filter2Resonance].setParam = filterSetters[1].setQ;
	params[Filter2Gain].setParam = filterSetters[1].setGain;
	params[Envelope1Attack].setParam = &setEnvelopeAttack;
	params[Envelope1Decay].setParam = &setEnvelopeDecay;
	params[Envelope1Sustain].setParam = &setEnvelopeSustain;
	params[Envelope1Release].setParam = &setEnvelopeRelease;
	params[Envelope1Leak].setParam = &setEnvelopeLeak;
	params[Envelope2Attack].setParam = &setEnvelopeAttack;
	params[Envelope2Decay].setParam = &setEnvelopeDecay;
	params[Envelope2Sustain].setParam = &setEnvelopeSustain;
	params[Envelope2Release].setParam = &setEnvelopeRelease;
	params[Envelope2Leak].setParam = &setEnvelopeLeak;
	params[Envelope3Attack].setParam = &setEnvelopeAttack;
	params[Envelope3Decay].setParam = &setEnvelopeDecay;
	params[Envelope3Sustain].setParam = &setEnvelopeSustain;
	params[Envelope3Release].setParam = &setEnvelopeRelease;
	params[Envelope3Leak].setParam = &setEnvelopeLeak;
	params[Envelope4Attack].setParam = &setEnvelopeAttack;
	params[Envelope4Decay].setParam = &setEnvelopeDecay;
	params[Envelope4Sustain].setParam = &setEnvelopeSustain;
	params[Envelope4Release].setParam = &setEnvelopeRelease;
	params[Envelope4Leak].setParam = &setEnvelopeLeak;
	params[LFO1Rate].setParam = lfoSetters[0].setRate;
	params[LFO2Rate].setParam = lfoSetters[1].setRate;
	params[LFO3Rate].setParam = lfoSetters[2].setRate;
	params[LFO4Rate].setParam = lfoSetters[3].setRate;
	params[LFO1Shape].setParam = lfoSetters[0].setShape;
	params[LFO2Shape].setParam = lfoSetters[1].setShape;
	params[LFO3Shape].setParam = lfoSetters[2].setShape;
	params[LFO4Shape].setParam = lfoSetters[3].setShape;
	params[LFO1Phase].setParam = lfoSetters[0].setPhase;
	params[LFO2Phase].setParam = lfoSetters[1].setPhase;
	params[LFO3Phase].setParam = lfoSetters[2].setPhase;
	params[LFO4Phase].setParam = lfoSetters[3].setPhase;
	params[OutputAmp].setParam = &setAmp;

	for (int i = 0; i < NUM_PARAMS; i++)
	{
		params[i].objectNumber = 0;
		//oscillators
		if ((i >= Osc1) && (i < Osc2))
		{
			params[i].objectNumber = 0;
		}
		else if ((i >= Osc2) && (i < Osc3))
		{
			params[i].objectNumber = 1;
		}
		else if ((i >= Osc3) && (i < Effect1FXType))
		{
			params[i].objectNumber = 2;
		}
		//effects
		//filters
		else if ((i >= Filter1) && (i < Filter2))
		{
			params[i].objectNumber = 0;
		}
		else if ((i >= Filter2) && (i < Envelope1Attack))
		{
			params[i].objectNumber = 1;
		}
		//envelopes
		else if ((i >= Envelope1Attack) && (i < Envelope2Attack))
		{
			params[i].objectNumber = 0;
		}
		else if ((i >= Envelope2Attack) && (i < Envelope3Attack))
		{
			params[i].objectNumber = 1;
		}
		else if ((i >= Envelope3Attack) && (i < Envelope4Attack))
		{
			params[i].objectNumber = 2;
		}
		else if ((i >= Envelope4Attack) && (i < LFO1Rate))
		{
			params[i].objectNumber = 3;
		}
		//lfos
		else if ((i >= LFO1Rate) && (i < LFO2Rate))
		{
			params[i].objectNumber = 0;
		}
		else if ((i >= LFO2Rate) && (i < LFO3Rate))
		{
			params[i].objectNumber = 1;
		}
		else if ((i >= LFO3Rate) && (i < LFO4Rate))
		{
			params[i].objectNumber = 2;
		}
		else if ((i >= LFO4Rate) && (i < OutputAmp))
		{
			params[i].objectNumber = 3;
		}
		//effects
		else if ((i >= Effect1FXType) && (i < Effect2FXType))
		{
			params[i].objectNumber = 0;
		}
		else if ((i >= Effect2FXType) && (i < Effect3FXType))
		{
			params[i].objectNumber = 1;
		}
		else if ((i >= Effect3FXType) && (i < Effect4FXType))
		{
			params[i].objectNumber = 2;
		}
		else if ((i >= Effect4FXType) && (i < Filter1))
		{
			params[i].objectNumber = 3;
		}

		params[i].setParam(params[i].realVal, params[i].objectNumber);

	}

	midiKeyDivisor = 1.0f / ((params[MIDIKeyMax].realVal*127.0f) - (params[MIDIKeyMin].realVal*127.0f));
	midiKeySubtractor = (params[MIDIKeyMin].realVal * 127.0f);
	//mappings parsing

	//move past the countcheck elements (already checked earlier)
	bufferIndex += 2;

	//move past the mappingCount elements (already stored that value earlier)
	bufferIndex += 2;

	numMappings = 0;
	for (int i = 0; i < NUM_LFOS; i++)
	{
		lfoOn[i] = 0;
	}
	//blank out all current mappings
	for (int i = 0; i < MAX_NUM_MAPPINGS; i++)
	{
		mappings[i].destNumber = 255;
		mappings[i].numHooks = 0;
	}

	for (int i = 0; i < mappingCount; i++)
	{
		uint8_t destNumber = buffer[bufferIndex+1];
		uint8_t whichMapping = 0;
		uint8_t whichHook = 0;
		uint8_t foundOne = 0;

		//search to see if this destination already has other mappings
		for (int j = 0; j < MAX_NUM_MAPPINGS; j++)
		{
			if (mappings[j].destNumber == destNumber)
			{
				//found one, use this mapping and add another hook to it
				whichMapping = j;
				whichHook = mappings[j].numHooks;
				foundOne = 1;
			}
		}
		if (foundOne == 0)
		{
			//didn't find another mapping with this destination, start a new mapping
			whichMapping = numMappings;

			numMappings++;
			whichHook = 0;
			mappings[whichMapping].destNumber = destNumber;
			mappings[whichMapping].dest = &params[destNumber];

		}
		mappings[whichMapping].sourceSmoothed[whichHook] = 1;

		int source = buffer[bufferIndex];

		mappings[whichMapping].sourceValPtr[whichHook] = &sourceValues[source];

//TODO: fix then when it's no longer temp macros
		if (source < 12) //if it's oscillators or noise (the first 4 elements of the source array), don't smooth to allow FM
		{
			mappings[whichMapping].sourceSmoothed[whichHook] = 0;

		}
		if ((source >= LFO_SOURCE_OFFSET) && (source < (LFO_SOURCE_OFFSET + NUM_LFOS)))
		{
			lfoOn[source - LFO_SOURCE_OFFSET] = 1;
		}
		int scalar = buffer[bufferIndex+2];
		if (scalar == 0xff)
		{
			mappings[whichMapping].scalarSourceValPtr[whichHook] = &defaultScaling;
		}
		else
		{
			mappings[whichMapping].scalarSourceValPtr[whichHook] = &sourceValues[buffer[bufferIndex+2]];
			if ((scalar >= LFO_SOURCE_OFFSET) && (scalar < (LFO_SOURCE_OFFSET + NUM_LFOS)))
			{
				lfoOn[scalar - LFO_SOURCE_OFFSET] = 1;
			}
		}
		int16_t amountInt = (buffer[bufferIndex+3] << 8) + buffer[bufferIndex+4];
		float amountFloat = (float)amountInt * INV_TWO_TO_15;
//		//if the source is bipolar (oscillators, noise, and LFOs) then double the amount because it comes in as only half the range
//		if ((source < 4) || ((source >= LFO_SOURCE_OFFSET) && (source < (LFO_SOURCE_OFFSET + NUM_LFOS))))
//		{
//			amountFloat *= 2.0f;
//		}
		mappings[whichMapping].amount[whichHook] = amountFloat;
		mappings[whichMapping].numHooks++;

		bufferIndex += 5;
	}

	audioMasterLevel = 1.0f;
	presetWaitingToParse = 0;
	currentActivePreset = presetNumber;
	__enable_irq();
}

/////

void  __ATTR_ITCMRAM HAL_SPI_TxRxCpltCallback(SPI_HandleTypeDef *hspi)
{
	handleSPI(16);
}

void __ATTR_ITCMRAM HAL_SPI_TxRxHalfCpltCallback(SPI_HandleTypeDef *hspi)
{
	handleSPI(0);
}

void FlushECC(void *ptr, int bytes)
{

	uint32_t addr = (uint32_t)ptr;
	/* Check if accessing AXI SRAM => 64-bit words*/
	if(addr >= 0x24000000 && addr < 0x24080000){
		volatile uint64_t temp;
		volatile uint64_t* flush_ptr = (uint64_t*) (addr & 0xFFFFFFF8);
		uint64_t *end_ptr = (uint64_t*) ((addr+bytes) & 0xFFFFFFF8);

		do{
			temp = *flush_ptr;
			*flush_ptr = temp;
			flush_ptr++;
		}while(flush_ptr != end_ptr);
	}
	/* Otherwise 32-bit words */
	else {
		volatile uint32_t temp;
		volatile uint32_t* flush_ptr = (uint32_t*) (addr & 0xFFFFFFFC);
		uint32_t *end_ptr = (uint32_t*) ((addr+bytes) & 0xFFFFFFFC);

		do{
			temp = *flush_ptr;
			*flush_ptr = temp;
			flush_ptr++;
		}while(flush_ptr != end_ptr);
	}
}
// helper function to initialize measuring unit (cycle counter) */
void CycleCounterInit( void )
{
  /* Enable TRC */
  CoreDebug->DEMCR |= CoreDebug_DEMCR_TRCENA_Msk;

  /* Unlock DWT registers */
  if ((*(uint32_t*)0xE0001FB4) & 1)
    *(uint32_t*)0xE0001FB0 = 0xC5ACCE55;

  /* clear the cycle counter */
  DWT->CYCCNT = 0;

  /* start the cycle counter */
  DWT->CTRL = 0x40000001;

}

// EXTI Line12 External Interrupt ISR Handler CallBackFun
void HAL_GPIO_EXTI_Callback(uint16_t GPIO_Pin)
{

	/*if(GPIO_Pin == GPIO_PIN_12) // If The INT Source Is EXTI Line12
    {

    	  if(HAL_GPIO_ReadPin(GPIOB, GPIO_PIN_12) == 0)
    	  {
    		  HAL_SPI_Abort(&hspi1);
    		  __HAL_SPI_CLEAR_OVRFLAG(&hspi1);
    	  }
    	  else
    	  {
    		  for (int i = 0; i < 32; i++)
			  {
				  SPI_TX[i] = i;
			  }

			  HAL_SPI_TransmitReceive_DMA(&hspi1, SPI_TX, SPI_RX, 32);
    	  }
    }
    */
    if(GPIO_Pin == GPIO_PIN_3) // If The INT Source Is EXTI Line3
    {
    	  if(HAL_GPIO_ReadPin(GPIOG, GPIO_PIN_3) == 1) //button is pressed, wait
    	  {
    		  buttonPressed = 1;
    		  //bootloadFlag = 231;
    		  //*(__IO uint32_t*)(0x38800000+36) = 12345678;
    		  //SCB_CleanDCache_by_Addr (*(__IO uint32_t*)0x38800000+36, 1); //maybe needs different
    	  }
    	  else //button went up
    	  {
    		  if (buttonPressed == 1)
    		  {
    			  for (int i = 0; i < 32; i++)
    			  {
    				  bootloaderFlag[i] = 231;
    			  }
    			  FlushECC(&bootloaderFlag,  32);

				  buttonPressed = 0;

				  HAL_Delay(100);
				  HAL_NVIC_SystemReset();

    		  }
    	  }
    }
}

/* USER CODE END 4 */

void Error_Handler(void)
{
  __disable_irq();
  while (1)
  {
  }
}
